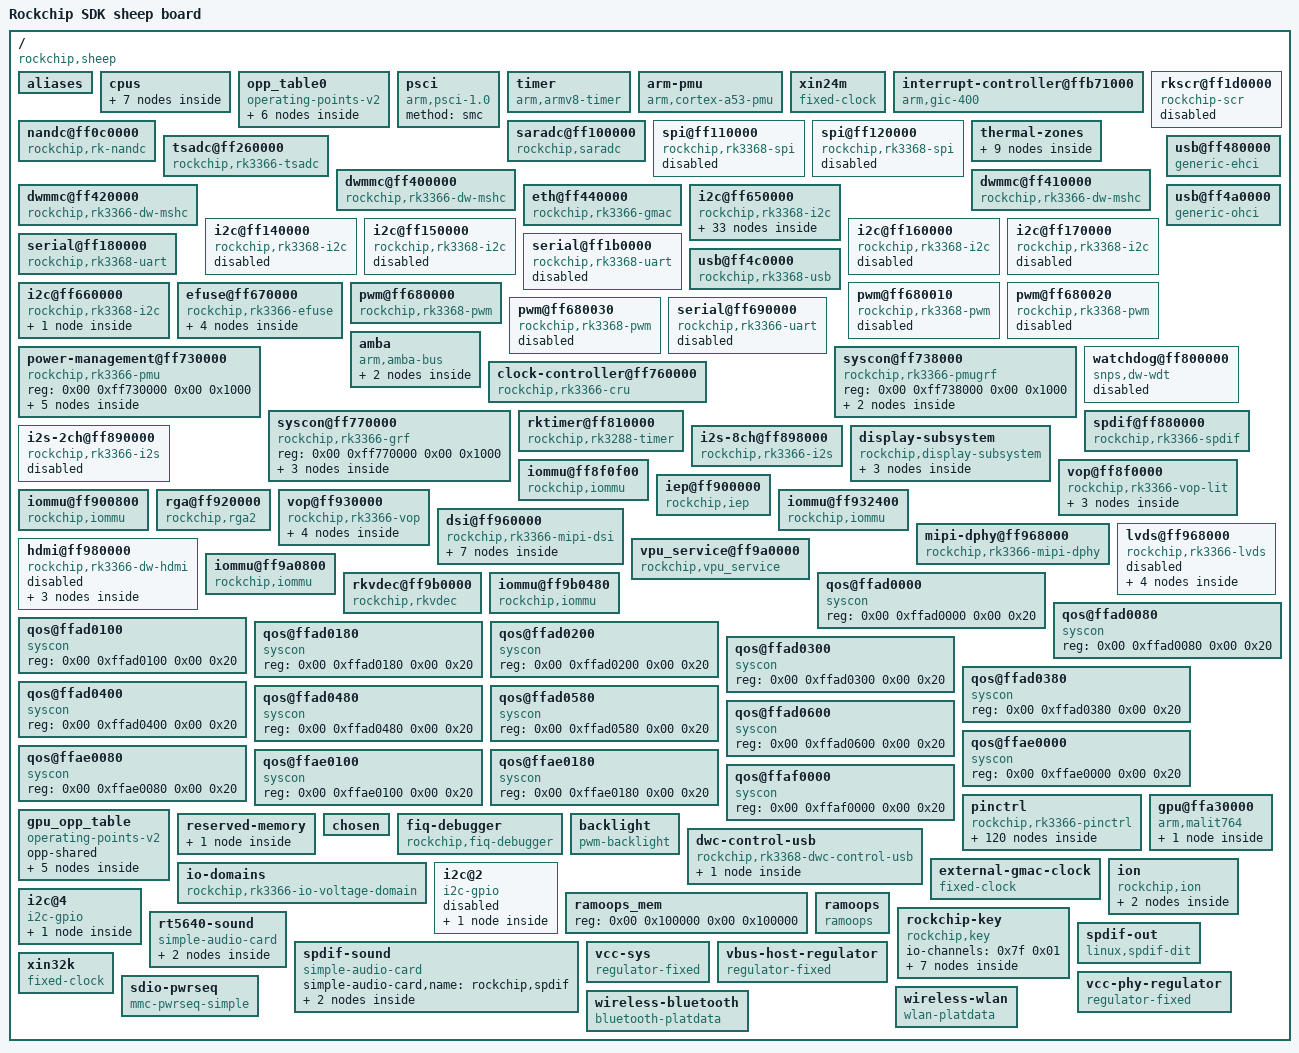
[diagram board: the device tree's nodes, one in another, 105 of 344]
/dts-v1/;

/ {
	compatible = "rockchip,sheep\0rockchip,rk3366";
	interrupt-parent = <0x01>;
	#address-cells = <0x02>;
	#size-cells = <0x02>;
	model = "Rockchip SDK sheep board";

	aliases {
		i2c0 = "/i2c@ff650000";
		i2c1 = "/i2c@ff660000";
		i2c2 = "/i2c@ff140000";
		i2c3 = "/i2c@ff150000";
		i2c4 = "/i2c@ff160000";
		i2c5 = "/i2c@ff170000";
		serial0 = "/serial@ff180000";
		serial2 = "/serial@ff690000";
		serial3 = "/serial@ff1b0000";
		spi0 = "/spi@ff110000";
		spi1 = "/spi@ff120000";
	};

	cpus {
		#address-cells = <0x02>;
		#size-cells = <0x00>;

		cpu@0 {
			device_type = "cpu";
			compatible = "arm,cortex-a53\0arm,armv8";
			reg = <0x00 0x00>;
			enable-method = "psci";
			clocks = <0x02 0x09>;
			operating-points-v2 = <0x03>;
			cpu-idle-states = <0x04 0x05>;
			#cooling-cells = <0x02>;
			dynamic-power-coefficient = <0xa6>;
			cpu-supply = <0x06>;
			phandle = <0x08>;
		};

		cpu@1 {
			device_type = "cpu";
			compatible = "arm,cortex-a53\0arm,armv8";
			reg = <0x00 0x01>;
			enable-method = "psci";
			operating-points-v2 = <0x03>;
			cpu-idle-states = <0x04 0x05>;
			cpu-supply = <0x06>;
			phandle = <0x09>;
		};

		cpu@2 {
			device_type = "cpu";
			compatible = "arm,cortex-a53\0arm,armv8";
			reg = <0x00 0x02>;
			enable-method = "psci";
			operating-points-v2 = <0x03>;
			cpu-idle-states = <0x04 0x05>;
			cpu-supply = <0x06>;
			phandle = <0x0a>;
		};

		cpu@3 {
			device_type = "cpu";
			compatible = "arm,cortex-a53\0arm,armv8";
			reg = <0x00 0x03>;
			enable-method = "psci";
			operating-points-v2 = <0x03>;
			cpu-idle-states = <0x04 0x05>;
			cpu-supply = <0x06>;
			phandle = <0x0b>;
		};

		idle-states {
			entry-method = "psci";

			cpu-sleep {
				compatible = "arm,idle-state";
				local-timer-stop;
				arm,psci-suspend-param = <0x10000>;
				entry-latency-us = <0x78>;
				exit-latency-us = <0xfa>;
				min-residency-us = <0x384>;
				phandle = <0x04>;
			};

			cluster-sleep {
				compatible = "arm,idle-state";
				local-timer-stop;
				arm,psci-suspend-param = <0x1010000>;
				entry-latency-us = <0x190>;
				exit-latency-us = <0x1f4>;
				min-residency-us = <0x7d0>;
				phandle = <0x05>;
			};
		};
	};

	opp_table0 {
		compatible = "operating-points-v2";
		opp-shared;
		nvmem-cells = <0x07>;
		nvmem-cell-names = "cpu_leakage";
		phandle = <0x03>;

		opp-408000000 {
			opp-hz = <0x00 0x18519600>;
			opp-microvolt = <0xe7ef0 0xe7ef0 0x1312d0>;
			clock-latency-ns = <0x9c40>;
			opp-suspend;
		};

		opp-600000000 {
			opp-hz = <0x00 0x23c34600>;
			opp-microvolt = <0xe7ef0 0xe7ef0 0x1312d0>;
		};

		opp-816000000 {
			opp-hz = <0x00 0x30a32c00>;
			opp-microvolt = <0xf4240 0xf4240 0x1312d0>;
		};

		opp-1008000000 {
			opp-hz = <0x00 0x3c14dc00>;
			opp-microvolt = <0x106738 0x106738 0x1312d0>;
		};

		opp-1200000000 {
			opp-hz = <0x00 0x47868c00>;
			opp-microvolt = <0x11edd8 0x11edd8 0x1312d0>;
		};

		opp-1296000000 {
			opp-hz = <0x00 0x4d3f6400>;
			opp-microvolt = <0x1312d0 0x1312d0 0x1312d0>;
		};
	};

	psci {
		compatible = "arm,psci-1.0";
		method = "smc";
	};

	timer {
		compatible = "arm,armv8-timer";
		interrupts = <0x01 0x0d 0xf04 0x01 0x0e 0xf04 0x01 0x0b 0xf04 0x01 0x0a 0xf04>;
	};

	arm-pmu {
		compatible = "arm,cortex-a53-pmu";
		interrupts = <0x00 0x70 0x04 0x00 0x71 0x04 0x00 0x72 0x04 0x00 0x73 0x04>;
		interrupt-affinity = <0x08 0x09 0x0a 0x0b>;
	};

	xin24m {
		compatible = "fixed-clock";
		#clock-cells = <0x00>;
		clock-frequency = <0x16e3600>;
		clock-output-names = "xin24m";
		phandle = <0x8b>;
	};

	interrupt-controller@ffb71000 {
		compatible = "arm,gic-400";
		interrupt-controller;
		#interrupt-cells = <0x03>;
		#address-cells = <0x00>;
		reg = <0x00 0xffb71000 0x00 0x1000 0x00 0xffb72000 0x00 0x1000 0x00 0xffb74000 0x00 0x2000 0x00 0xffb76000 0x00 0x2000>;
		interrupts = <0x01 0x09 0xf04>;
		phandle = <0x01>;
	};

	nandc@ff0c0000 {
		compatible = "rockchip,rk-nandc";
		reg = <0x00 0xff0c0000 0x00 0x4000>;
		interrupts = <0x00 0x26 0x04>;
		nandc_id = <0x00>;
		clocks = <0x02 0x64 0x02 0x1ca>;
		clock-names = "clk_nandc\0hclk_nandc";
		status = "okay";
		phandle = <0x8c>;
	};

	saradc@ff100000 {
		compatible = "rockchip,saradc";
		reg = <0x00 0xff100000 0x00 0x100>;
		interrupts = <0x00 0x24 0x04>;
		#io-channel-cells = <0x01>;
		clocks = <0x02 0x63 0x02 0x161>;
		clock-names = "saradc\0apb_pclk";
		status = "okay";
		phandle = <0x7f>;
	};

	spi@ff110000 {
		compatible = "rockchip,rk3368-spi\0rockchip,rk3066-spi";
		reg = <0x00 0xff110000 0x00 0x1000>;
		clocks = <0x02 0x4e 0x02 0x156>;
		clock-names = "spiclk\0apb_pclk";
		interrupts = <0x00 0x2c 0x04>;
		pinctrl-names = "default";
		pinctrl-0 = <0x0c 0x0d 0x0e 0x0f>;
		#address-cells = <0x01>;
		#size-cells = <0x00>;
		status = "disabled";
		phandle = <0x8d>;
	};

	spi@ff120000 {
		compatible = "rockchip,rk3368-spi\0rockchip,rk3066-spi";
		reg = <0x00 0xff120000 0x00 0x1000>;
		clocks = <0x02 0x4f 0x02 0x157>;
		clock-names = "spiclk\0apb_pclk";
		interrupts = <0x00 0x2d 0x04>;
		pinctrl-names = "default";
		pinctrl-0 = <0x10 0x11 0x12 0x13>;
		#address-cells = <0x01>;
		#size-cells = <0x00>;
		status = "disabled";
		phandle = <0x8e>;
	};

	rkscr@ff1d0000 {
		compatible = "rockchip-scr";
		reg = <0x00 0xff1d0000 0x00 0x10000>;
		interrupts = <0x00 0x2b 0x04>;
		#address-cells = <0x01>;
		#size-cells = <0x00>;
		pinctrl-names = "default";
		pinctrl-0 = <0x14 0x15 0x16 0x17>;
		clocks = <0x02 0x163>;
		clock-names = "g_pclk_sim_card";
		status = "disabled";
		phandle = <0x8f>;
	};

	thermal-zones {

		soc-thermal {
			polling-delay-passive = <0x64>;
			polling-delay = <0x3e8>;
			sustainable-power = <0x640>;
			thermal-sensors = <0x18 0x00>;
			phandle = <0x90>;

			trips {

				trip-point-0 {
					temperature = <0x11170>;
					hysteresis = <0x7d0>;
					type = "passive";
					phandle = <0x91>;
				};

				trip-point-1 {
					temperature = <0x14c08>;
					hysteresis = <0x7d0>;
					type = "passive";
					phandle = <0x19>;
				};

				soc-crit {
					temperature = <0x1c138>;
					hysteresis = <0x7d0>;
					type = "critical";
					phandle = <0x92>;
				};
			};

			cooling-maps {

				map0 {
					trip = <0x19>;
					cooling-device = <0x08 0xffffffff 0xffffffff>;
				};

				map1 {
					trip = <0x19>;
					cooling-device = <0x1a 0xffffffff 0xffffffff>;
				};
			};
		};

		gpu-thermal {
			polling-delay-passive = <0x64>;
			polling-delay = <0x3e8>;
			thermal-sensors = <0x18 0x01>;
			phandle = <0x93>;
		};
	};

	tsadc@ff260000 {
		compatible = "rockchip,rk3366-tsadc";
		reg = <0x00 0xff260000 0x00 0x100>;
		interrupts = <0x00 0x25 0x04>;
		clocks = <0x02 0x62 0x02 0x162>;
		clock-names = "tsadc\0apb_pclk";
		resets = <0x02 0x8e>;
		reset-names = "tsadc-apb";
		pinctrl-names = "gpio\0otpout";
		pinctrl-0 = <0x1b>;
		pinctrl-1 = <0x1c>;
		#thermal-sensor-cells = <0x01>;
		rockchip,hw-tshut-temp = <0x1d4c0>;
		status = "okay";
		phandle = <0x18>;
	};

	dwmmc@ff400000 {
		compatible = "rockchip,rk3366-dw-mshc\0rockchip,rk3288-dw-mshc";
		clock-freq-min-max = <0x61a80 0x23c3460>;
		clocks = <0x02 0x1c7 0x02 0x51 0x02 0x55 0x02 0x56>;
		clock-names = "biu\0ciu\0ciu-drive\0ciu-sample";
		fifo-depth = <0x100>;
		interrupts = <0x00 0x20 0x04>;
		reg = <0x00 0xff400000 0x00 0x4000>;
		status = "okay";
		clock-frequency = <0x23c3460>;
		supports-sd;
		bus-width = <0x04>;
		cap-mmc-highspeed;
		cap-sd-highspeed;
		card-detect-delay = <0xc8>;
		disable-wp;
		num-slots = <0x01>;
		pinctrl-names = "default";
		pinctrl-0 = <0x1d 0x1e 0x1f 0x20>;
		phandle = <0x94>;
	};

	dwmmc@ff410000 {
		compatible = "rockchip,rk3366-dw-mshc\0rockchip,rk3288-dw-mshc";
		clock-freq-min-max = <0x30d40 0x23c3460>;
		clocks = <0x02 0x1c8 0x02 0x52 0x02 0x57 0x02 0x58>;
		clock-names = "biu\0ciu\0ciu-drive\0ciu-sample";
		fifo-depth = <0x100>;
		interrupts = <0x00 0x21 0x04>;
		reg = <0x00 0xff410000 0x00 0x4000>;
		status = "okay";
		clock-frequency = <0x23c3460>;
		supports-sdio;
		bus-width = <0x04>;
		disable-wp;
		cap-sd-highspeed;
		cap-sdio-irq;
		keep-power-in-suspend;
		mmc-pwrseq = <0x21>;
		non-removable;
		num-slots = <0x01>;
		pinctrl-names = "default";
		pinctrl-0 = <0x22 0x23 0x24>;
		sd-uhs-sdr104;
		phandle = <0x95>;
	};

	dwmmc@ff420000 {
		compatible = "rockchip,rk3366-dw-mshc\0rockchip,rk3288-dw-mshc";
		clock-freq-min-max = <0x61a80 0x5f5e100>;
		clocks = <0x02 0x1c9 0x02 0x54 0x02 0x5b 0x02 0x5c>;
		clock-names = "biu\0ciu\0ciu-drive\0ciu-sample";
		fifo-depth = <0x100>;
		interrupts = <0x00 0x23 0x04>;
		reg = <0x00 0xff420000 0x00 0x4000>;
		status = "okay";
		clock-frequency = <0x5f5e100>;
		supports-emmc;
		bus-width = <0x08>;
		cap-mmc-highspeed;
		disable-wp;
		non-removable;
		num-slots = <0x01>;
		pinctrl-names = "default";
		pinctrl-0 = <0x25 0x26 0x27 0x28>;
		phandle = <0x96>;
	};

	eth@ff440000 {
		compatible = "rockchip,rk3366-gmac";
		reg = <0x00 0xff440000 0x00 0x10000>;
		rockchip,grf = <0x29>;
		interrupts = <0x00 0x1b 0x04>;
		interrupt-names = "macirq";
		clocks = <0x02 0x6b 0x02 0x6e 0x02 0x6f 0x02 0x6d 0x02 0x6c 0x02 0xc7 0x02 0x155>;
		clock-names = "stmmaceth\0mac_clk_rx\0mac_clk_tx\0clk_mac_ref\0clk_mac_refout\0aclk_mac\0pclk_mac";
		resets = <0x02 0x42>;
		reset-names = "stmmaceth";
		status = "okay";
		phy-supply = <0x2a>;
		phy-mode = "rgmii";
		clock_in_out = "input";
		snps,reset-gpio = <0x2b 0x0f 0x01>;
		snps,reset-active-low;
		snps,reset-delays-us = <0x00 0x2710 0xc350>;
		assigned-clocks = <0x02 0x6b>;
		assigned-clock-parents = <0x2c>;
		pinctrl-names = "default";
		pinctrl-0 = <0x2d>;
		tx_delay = <0x25>;
		rx_delay = <0x1d>;
		phandle = <0x97>;
	};

	i2c@ff650000 {
		compatible = "rockchip,rk3368-i2c\0rockchip,rk3288-i2c";
		reg = <0x00 0xff728000 0x00 0x1000>;
		clocks = <0x02 0x158>;
		clock-names = "i2c";
		interrupts = <0x00 0x3c 0x04>;
		pinctrl-names = "default";
		pinctrl-0 = <0x2e>;
		#address-cells = <0x01>;
		#size-cells = <0x00>;
		status = "okay";
		i2c-scl-rising-time-ns = <0xfa>;
		i2c-scl-falling-time-ns = <0x14>;
		phandle = <0x98>;

		syr827@40 {
			regulator-name = "vdd_arm";
			compatible = "silergy,syr827";
			status = "okay";
			reg = <0x40>;
			regulator-compatible = "fan53555-reg";
			regulator-min-microvolt = <0xadf34>;
			regulator-max-microvolt = <0x16e360>;
			fcs,suspend-voltage-selector = <0x01>;
			regulator-always-on;
			regulator-boot-on;
			regulator-initial-state = <0x03>;
			regulator-ramp-delay = <0x7d0>;
			phandle = <0x06>;

			regulator-state-mem {
				regulator-off-in-suspend;
				regulator-suspend-microvolt = <0xdbba0>;
			};
		};

		pmic@1c {
			compatible = "rockchip,rk818";
			status = "okay";
			reg = <0x1c>;
			clock-output-names = "rk818-clkout1\0wifibt_32kin";
			interrupt-parent = <0x2f>;
			interrupts = <0x02 0x08>;
			pinctrl-names = "default";
			pinctrl-0 = <0x30>;
			rockchip,system-power-controller;
			wakeup-source;
			#clock-cells = <0x01>;
			vcc1-supply = <0x31>;
			vcc2-supply = <0x31>;
			vcc3-supply = <0x31>;
			vcc4-supply = <0x31>;
			vcc6-supply = <0x31>;
			vcc7-supply = <0x31>;
			vcc8-supply = <0x31>;
			vcc9-supply = <0x32>;
			phandle = <0x86>;

			regulators {

				DCDC_REG1 {
					regulator-name = "vdd_logic";
					regulator-always-on;
					regulator-boot-on;
					regulator-min-microvolt = <0xb71b0>;
					regulator-max-microvolt = <0x162010>;
					regulator-ramp-delay = <0x1771>;
					phandle = <0x74>;

					regulator-state-mem {
						regulator-on-in-suspend;
						regulator-suspend-microvolt = <0xf4240>;
					};
				};

				DCDC_REG2 {
					regulator-name = "vdd_gpu";
					regulator-always-on;
					regulator-boot-on;
					regulator-min-microvolt = "\0\f5";
					regulator-max-microvolt = <0x1312d0>;
					regulator-ramp-delay = <0x1771>;
					phandle = <0x99>;

					regulator-state-mem {
						regulator-on-in-suspend;
						regulator-suspend-microvolt = <0xf4240>;
					};
				};

				DCDC_REG3 {
					regulator-name = "vcc_ddr";
					regulator-always-on;
					regulator-boot-on;
					phandle = <0x9a>;

					regulator-state-mem {
						regulator-on-in-suspend;
					};
				};

				DCDC_REG4 {
					regulator-name = "vcc_io";
					regulator-always-on;
					regulator-boot-on;
					regulator-min-microvolt = <0x325aa0>;
					regulator-max-microvolt = <0x325aa0>;
					phandle = <0x32>;

					regulator-state-mem {
						regulator-on-in-suspend;
						regulator-suspend-microvolt = <0x325aa0>;
					};
				};

				LDO_REG1 {
					regulator-name = "vcca_codec";
					regulator-always-on;
					regulator-boot-on;
					regulator-min-microvolt = <0x325aa0>;
					regulator-max-microvolt = <0x325aa0>;
					phandle = <0x9b>;

					regulator-state-mem {
						regulator-on-in-suspend;
						regulator-suspend-microvolt = <0x325aa0>;
					};
				};

				LDO_REG2 {
					regulator-name = "vcc_tp";
					regulator-always-on;
					regulator-boot-on;
					regulator-min-microvolt = <0x2dc6c0>;
					regulator-max-microvolt = <0x2dc6c0>;
					phandle = <0x7d>;

					regulator-state-mem {
						regulator-on-in-suspend;
						regulator-suspend-microvolt = <0x2dc6c0>;
					};
				};

				LDO_REG3 {
					regulator-name = "vdd_10";
					regulator-always-on;
					regulator-boot-on;
					regulator-min-microvolt = <0xf4240>;
					regulator-max-microvolt = <0xf4240>;
					phandle = <0x9c>;

					regulator-state-mem {
						regulator-on-in-suspend;
						regulator-suspend-microvolt = <0xf4240>;
					};
				};

				LDO_REG4 {
					regulator-name = "vcc18_lcd";
					regulator-always-on;
					regulator-boot-on;
					regulator-min-microvolt = <0x1b7740>;
					regulator-max-microvolt = <0x1b7740>;
					phandle = <0x9d>;

					regulator-state-mem {
						regulator-on-in-suspend;
						regulator-suspend-microvolt = <0x1b7740>;
					};
				};

				LDO_REG5 {
					regulator-name = "vccio_pmu";
					regulator-always-on;
					regulator-boot-on;
					regulator-min-microvolt = <0x1b7740>;
					regulator-max-microvolt = <0x1b7740>;
					phandle = <0x9e>;

					regulator-state-mem {
						regulator-on-in-suspend;
						regulator-suspend-microvolt = <0x1b7740>;
					};
				};

				LDO_REG6 {
					regulator-name = "vdd10_lcd";
					regulator-always-on;
					regulator-boot-on;
					regulator-min-microvolt = <0xf4240>;
					regulator-max-microvolt = <0xf4240>;
					phandle = <0x9f>;

					regulator-state-mem {
						regulator-on-in-suspend;
						regulator-suspend-microvolt = <0xf4240>;
					};
				};

				LDO_REG7 {
					regulator-name = "vcc_18";
					regulator-always-on;
					regulator-boot-on;
					regulator-min-microvolt = <0x1b7740>;
					regulator-max-microvolt = <0x1b7740>;
					phandle = <0x76>;

					regulator-state-mem {
						regulator-on-in-suspend;
						regulator-suspend-microvolt = <0x1b7740>;
					};
				};

				LDO_REG8 {
					regulator-name = "vccio_wl";
					regulator-always-on;
					regulator-boot-on;
					regulator-min-microvolt = <0x1b7740>;
					regulator-max-microvolt = <0x325aa0>;
					phandle = <0x77>;

					regulator-state-mem {
						regulator-on-in-suspend;
						regulator-suspend-microvolt = <0x325aa0>;
					};
				};

				LDO_REG9 {
					regulator-name = "vccio_sd";
					regulator-always-on;
					regulator-boot-on;
					regulator-min-microvolt = <0x1b7740>;
					regulator-max-microvolt = <0x325aa0>;
					phandle = <0x78>;

					regulator-state-mem {
						regulator-on-in-suspend;
						regulator-suspend-microvolt = <0x325aa0>;
					};
				};

				SWITCH_REG {
					regulator-name = "vcc_sd";
					regulator-always-on;
					regulator-boot-on;
					phandle = <0xa0>;

					regulator-state-mem {
						regulator-on-in-suspend;
					};
				};
			};

			battery {
				compatible = "rk818-battery";
				ocv_table = <0xd48 0xe42 0xe6d 0xe7b 0xe93 0xea5 0xeb0 0xeba 0xec6 0xed4 0xee4 0xef5 0xf0c 0xf2a 0xf4b 0xf6f 0xf8d 0xfcf 0xff6 0x1024 0x1056>;
				design_capacity = <0x1eec>;
				design_qmax = <0x2204>;
				bat_res = <0x41>;
				max_input_current = <0x7d0>;
				max_chrg_current = <0x640>;
				max_chrg_voltage = <0x1068>;
				sleep_enter_current = <0x12c>;
				sleep_exit_current = <0x12c>;
				power_off_thresd = <0xd48>;
				zero_algorithm_vol = <0xf0a>;
				fb_temperature = <0x69>;
				sample_res = <0x14>;
				max_soc_offset = <0x3c>;
				energy_mode = <0x00>;
				monitor_sec = <0x05>;
				virtual_power = <0x00>;
				power_dc2otg = <0x00>;
			};
		};
	};

	i2c@ff140000 {
		compatible = "rockchip,rk3368-i2c\0rockchip,rk3288-i2c";
		reg = <0x00 0xff140000 0x00 0x1000>;
		interrupts = <0x00 0x3e 0x04>;
		#address-cells = <0x01>;
		#size-cells = <0x00>;
		clock-names = "i2c";
		clocks = <0x02 0x15a>;
		pinctrl-names = "default";
		pinctrl-0 = <0x33>;
		status = "disabled";
		phandle = <0xa1>;
	};

	i2c@ff150000 {
		compatible = "rockchip,rk3368-i2c\0rockchip,rk3288-i2c";
		reg = <0x00 0xff150000 0x00 0x1000>;
		interrupts = <0x00 0x3f 0x04>;
		#address-cells = <0x01>;
		#size-cells = <0x00>;
		clock-names = "i2c";
		clocks = <0x02 0x15b>;
		pinctrl-names = "default";
		pinctrl-0 = <0x34>;
		status = "disabled";
		phandle = <0xa2>;
	};

	i2c@ff160000 {
		compatible = "rockchip,rk3368-i2c\0rockchip,rk3288-i2c";
		reg = <0x00 0xff160000 0x00 0x1000>;
		interrupts = <0x00 0x40 0x04>;
		#address-cells = <0x01>;
		#size-cells = <0x00>;
		clock-names = "i2c";
		clocks = <0x02 0x15c>;
		pinctrl-names = "default";
		pinctrl-0 = <0x35>;
		status = "disabled";
		phandle = <0xa3>;
	};

	i2c@ff170000 {
		compatible = "rockchip,rk3368-i2c\0rockchip,rk3288-i2c";
		reg = <0x00 0xff170000 0x00 0x1000>;
		interrupts = <0x00 0x41 0x04>;
		#address-cells = <0x01>;
		#size-cells = <0x00>;
		clock-names = "i2c";
		clocks = <0x02 0x15d>;
		pinctrl-names = "default";
		pinctrl-0 = <0x36>;
		status = "disabled";
		phandle = <0xa4>;
	};

	serial@ff180000 {
		compatible = "rockchip,rk3368-uart\0snps,dw-apb-uart";
		reg = <0x00 0xff180000 0x00 0x100>;
		clock-frequency = <0x16e3600>;
		clocks = <0x02 0x66 0x02 0x15e>;
		clock-names = "baudclk\0apb_pclk";
		interrupts = <0x00 0x37 0x04>;
		reg-shift = <0x02>;
		reg-io-width = <0x04>;
		pinctrl-names = "default";
		pinctrl-0 = <0x37 0x38>;
		status = "okay";
		phandle = <0xa5>;
	};

	serial@ff1b0000 {
		compatible = "rockchip,rk3368-uart\0snps,dw-apb-uart";
		reg = <0x00 0xff1b0000 0x00 0x100>;
		clock-frequency = <0x16e3600>;
		clocks = <0x02 0x69 0x02 0x160>;
		clock-names = "baudclk\0apb_pclk";
		interrupts = <0x00 0x3a 0x04>;
		reg-shift = <0x02>;
		reg-io-width = <0x04>;
		pinctrl-names = "default";
		pinctrl-0 = <0x39 0x3a 0x3b>;
		status = "disabled";
		phandle = <0xa6>;
	};

	usb@ff480000 {
		compatible = "generic-ehci";
		reg = <0x00 0xff480000 0x00 0x20000>;
		interrupts = <0x00 0x18 0x04>;
		clocks = <0x02 0x79 0x02 0x1c6>;
		clock-names = "usbphy_480m\0hclk_host0";
		phys = <0x3c>;
		phy-names = "usb";
		status = "okay";
		assigned-clocks = <0x02 0x79>;
		assigned-clock-parents = <0x3d>;
		phandle = <0xa7>;
	};

	usb@ff4a0000 {
		compatible = "generic-ohci";
		reg = <0x00 0xff4a0000 0x00 0x20000>;
		interrupts = <0x00 0x19 0x04>;
		clocks = <0x02 0x79 0x02 0x1c6>;
		clock-names = "usbphy_480m\0hclk_host0";
		phys = <0x3c>;
		phy-names = "usb";
		status = "okay";
		phandle = <0xa8>;
	};

	usb@ff4c0000 {
		compatible = "rockchip,rk3368-usb\0rockchip,rk3066-usb\0snps,dwc2";
		reg = <0x00 0xff4c0000 0x00 0x40000>;
		interrupts = <0x00 0x17 0x04>;
		clocks = <0x02 0x79 0x02 0x1c5>;
		clock-names = "usbphy_480m\0otg";
		dr_mode = "otg";
		g-np-tx-fifo-size = <0x10>;
		g-rx-fifo-size = <0x118>;
		g-tx-fifo-size = <0x100 0x80 0x80 0x40 0x20 0x10>;
		g-use-dma;
		status = "okay";
		resets = <0x02 0x84 0x02 0x85 0x02 0x86>;
		reset-names = "otg_ahb\0otg_phy\0otg_controller";
		rockchip,usb-mode = <0x00>;
		phandle = <0xa9>;
	};

	i2c@ff660000 {
		compatible = "rockchip,rk3368-i2c\0rockchip,rk3288-i2c";
		reg = <0x00 0xff660000 0x00 0x1000>;
		interrupts = <0x00 0x3d 0x04>;
		#address-cells = <0x01>;
		#size-cells = <0x00>;
		clock-names = "i2c";
		clocks = <0x02 0x159>;
		pinctrl-names = "default";
		pinctrl-0 = <0x3e>;
		status = "okay";
		i2c-scl-rising-time-ns = <0x1cc>;
		i2c-scl-falling-time-ns = <0x0f>;
		phandle = <0xaa>;

		rt5640@1c {
			#sound-dai-cells = <0x00>;
			compatible = "realtek,rt5640";
			reg = <0x1c>;
			clocks = <0x02 0x41>;
			clock-names = "mclk";
			realtek,in1-differential;
			phandle = <0x81>;
		};
	};

	efuse@ff670000 {
		compatible = "rockchip,rk3366-efuse";
		reg = <0x00 0xff670000 0x00 0x20>;
		#address-cells = <0x01>;
		#size-cells = <0x01>;
		clocks = <0x02 0x16f>;
		clock-names = "pclk_efuse";
		phandle = <0xab>;

		cpu-leakage {
			reg = <0x17 0x01>;
			phandle = <0x07>;
		};

		gpu-leakage {
			reg = <0x18 0x01>;
			phandle = <0xac>;
		};

		logic-leakage {
			reg = <0x19 0x01>;
			phandle = <0xad>;
		};

		wafer-info {
			reg = <0x1c 0x01>;
			phandle = <0xae>;
		};
	};

	pwm@ff680000 {
		compatible = "rockchip,rk3368-pwm\0rockchip,rk3288-pwm";
		reg = <0x00 0xff680000 0x00 0x10>;
		#pwm-cells = <0x03>;
		pinctrl-names = "active";
		pinctrl-0 = <0x3f>;
		clocks = <0x02 0x154>;
		clock-names = "pwm";
		status = "okay";
		phandle = <0x75>;
	};

	pwm@ff680010 {
		compatible = "rockchip,rk3368-pwm\0rockchip,rk3288-pwm";
		reg = <0x00 0xff680010 0x00 0x10>;
		#pwm-cells = <0x03>;
		pinctrl-names = "active";
		pinctrl-0 = <0x40>;
		clocks = <0x02 0x154>;
		clock-names = "pwm";
		status = "disabled";
		phandle = <0xaf>;
	};

	pwm@ff680020 {
		compatible = "rockchip,rk3368-pwm\0rockchip,rk3288-pwm";
		reg = <0x00 0xff680020 0x00 0x10>;
		#pwm-cells = <0x03>;
		clocks = <0x02 0x154>;
		clock-names = "pwm";
		status = "disabled";
		phandle = <0xb0>;
	};

	pwm@ff680030 {
		compatible = "rockchip,rk3368-pwm\0rockchip,rk3288-pwm";
		reg = <0x00 0xff680030 0x00 0x10>;
		#pwm-cells = <0x03>;
		pinctrl-names = "active";
		pinctrl-0 = <0x41>;
		clocks = <0x02 0x154>;
		clock-names = "pwm";
		status = "disabled";
		phandle = <0xb1>;
	};

	serial@ff690000 {
		compatible = "rockchip,rk3366-uart\0snps,dw-apb-uart";
		reg = <0x00 0xff690000 0x00 0x100>;
		interrupts = <0x00 0x39 0x04>;
		clocks = <0x02 0x68 0x02 0x15f>;
		clock-names = "baudclk\0apb_pclk";
		reg-shift = <0x02>;
		reg-io-width = <0x04>;
		pinctrl-names = "default";
		pinctrl-0 = <0x42>;
		status = "disabled";
		phandle = <0xb2>;
	};

	power-management@ff730000 {
		compatible = "rockchip,rk3366-pmu\0syscon\0simple-mfd";
		reg = <0x00 0xff730000 0x00 0x1000>;
		phandle = <0xb3>;

		power-controller {
			compatible = "rockchip,rk3366-power-controller";
			#power-domain-cells = <0x01>;
			#address-cells = <0x01>;
			#size-cells = <0x00>;
			phandle = <0x5c>;

			pd_vio@6 {
				reg = <0x06>;
				clocks = <0x02 0xcc 0x02 0xd0 0x02 0xcb 0x02 0xd1 0x02 0xce 0x02 0xcd 0x02 0xcf 0x02 0xaa 0x02 0xab 0x02 0x1d0 0x02 0x1ce 0x02 0x1cf 0x02 0x1d1 0x02 0x1d2 0x02 0x1d6 0x02 0x14d 0x02 0x165 0x02 0x164 0x02 0x16c 0x02 0x46 0x02 0x4b 0x02 0x47 0x02 0x45 0x02 0x49 0x02 0x48>;
				pm_qos = <0x43 0x44 0x45 0x46 0x47 0x48 0x49 0x4a 0x4b 0x4c 0x4d>;
			};

			pd_vpu@10 {
				reg = <0x0a>;
				clocks = <0x02 0xc9 0x02 0x1cc>;
				pm_qos = <0x4e 0x4f>;
			};

			pd_rkvdec@8 {
				reg = <0x08>;
				clocks = <0x02 0xca 0x02 0x1cd 0x02 0x7d 0x02 0x7e>;
				pm_qos = <0x50 0x51>;
			};

			pd_gpu@11 {
				reg = <0x0b>;
				clocks = <0x02 0xc4>;
				pm_qos = <0x52>;
			};
		};
	};

	syscon@ff738000 {
		compatible = "rockchip,rk3366-pmugrf\0syscon\0simple-mfd";
		reg = <0x00 0xff738000 0x00 0x1000>;
		phandle = <0x6f>;

		reboot-mode {
			compatible = "syscon-reboot-mode";
			offset = <0x200>;
			mode-normal = <0x5242c300>;
			mode-recovery = <0x5242c303>;
			mode-fastboot = <0x5242c309>;
			mode-loader = <0x5242c301>;
		};

		pmu-pvtm {
			compatible = "rockchip,rk3366-pmu-pvtm";
			clocks = <0x02 0x81>;
			clock-names = "pmu";
			status = "okay";
			phandle = <0xb4>;
		};
	};

	amba {
		compatible = "arm,amba-bus";
		#address-cells = <0x02>;
		#size-cells = <0x02>;
		ranges;

		dma-controller@ff250000 {
			compatible = "arm,pl330\0arm,primecell";
			reg = <0x00 0xff250000 0x00 0x4000>;
			interrupts = <0x00 0x02 0x04 0x00 0x03 0x04>;
			#dma-cells = <0x01>;
			clocks = <0x02 0xc8>;
			clock-names = "apb_pclk";
			peripherals-req-type-burst;
			phandle = <0xb5>;
		};

		dma-controller@ff600000 {
			compatible = "arm,pl330\0arm,primecell";
			reg = <0x00 0xff600000 0x00 0x4000>;
			interrupts = <0x00 0x00 0x04 0x00 0x01 0x04>;
			#dma-cells = <0x01>;
			clocks = <0x02 0xc2>;
			clock-names = "apb_pclk";
			peripherals-req-type-burst;
			phandle = <0x54>;
		};
	};

	clock-controller@ff760000 {
		compatible = "rockchip,rk3366-cru";
		reg = <0x00 0xff760000 0x00 0x1000>;
		rockchip,grf = <0x29>;
		#clock-cells = <0x01>;
		#reset-cells = <0x01>;
		assigned-clocks = <0x02 0x72 0x02 0x84 0x02 0xaa 0x02 0xab 0x02 0x85 0x02 0x86 0x02 0x87 0x02 0x03 0x02 0x04 0x02 0x05 0x02 0x06 0x02 0x07 0x02 0x08 0x02 0xce 0x02 0xcd 0x02 0x1d2 0x02 0x1d2 0x02 0xd2 0x02 0xd3 0x02 0xd4>;
		assigned-clock-rates = <0x00 0x00 0x00 0x00 0x00 0x00 0x00 0x2cb41780 0x22551000 0x2367b880 0x2367b880 0x39387000 0x1efe9200 0x165a0bc0 0x112a8800 0x5f5e100 0x5f5e100 0x112a8800 0x112a8800 0x8954400>;
		assigned-clock-parents = <0x02 0x7a 0x02 0x83 0x02 0x82 0x02 0x05 0x02 0x04 0x02 0x04 0x02 0x04>;
		phandle = <0x02>;
	};

	syscon@ff770000 {
		compatible = "rockchip,rk3366-grf\0syscon\0simple-mfd";
		reg = <0x00 0xff770000 0x00 0x1000>;
		#address-cells = <0x01>;
		#size-cells = <0x01>;
		phandle = <0x29>;

		usb2-phy@700 {
			compatible = "rockchip,rk3366-usb2phy";
			reg = <0x700 0x2c>;
			clocks = <0x02 0x5d>;
			clock-names = "phyclk";
			#clock-cells = <0x00>;
			clock-output-names = "sclk_otgphy0_480m";
			phandle = <0x3d>;

			host-port {
				#phy-cells = <0x00>;
				interrupts = <0x00 0x60 0x04>;
				interrupt-names = "linestate";
				status = "okay";
				phy-supply = <0x53>;
				phandle = <0x3c>;
			};
		};

		pvtm {
			compatible = "rockchip,rk3366-pvtm";
			clocks = <0x02 0x4c 0x02 0x4d>;
			clock-names = "core\0gpu";
			status = "okay";
			phandle = <0xb6>;
		};
	};

	watchdog@ff800000 {
		compatible = "snps,dw-wdt";
		reg = <0x00 0xff800000 0x00 0x100>;
		clocks = <0x02 0x167>;
		interrupts = <0x00 0x4f 0x04>;
		status = "disabled";
		phandle = <0xb7>;
	};

	rktimer@ff810000 {
		compatible = "rockchip,rk3288-timer";
		reg = <0x00 0xff810000 0x00 0x1000>;
		interrupts = <0x00 0x42 0x04>;
		clocks = <0x02 0x14e 0x02 0x73>;
		clock-names = "pclk\0timer";
		phandle = <0xb8>;
	};

	spdif@ff880000 {
		compatible = "rockchip,rk3366-spdif";
		reg = <0x00 0xff880000 0x00 0x1000>;
		interrupts = <0x00 0x36 0x04>;
		dmas = <0x54 0x03>;
		dma-names = "tx";
		clock-names = "mclk\0hclk";
		clocks = <0x02 0x44 0x02 0x1c2>;
		pinctrl-names = "default";
		pinctrl-0 = <0x55>;
		status = "okay";
		#sound-dai-cells = <0x00>;
		phandle = <0x82>;
	};

	i2s-2ch@ff890000 {
		compatible = "rockchip,rk3366-i2s\0rockchip,rk3066-i2s";
		reg = <0x00 0xff890000 0x00 0x1000>;
		interrupts = <0x00 0x28 0x04>;
		dmas = <0x54 0x06 0x54 0x07>;
		dma-names = "tx\0rx";
		clock-names = "i2s_clk\0i2s_hclk";
		clocks = <0x02 0x43 0x02 0x1c1>;
		resets = <0x02 0x19>;
		reset-names = "reset-m";
		status = "disabled";
		phandle = <0xb9>;
	};

	i2s-8ch@ff898000 {
		compatible = "rockchip,rk3366-i2s\0rockchip,rk3066-i2s";
		reg = <0x00 0xff898000 0x00 0x1000>;
		interrupts = <0x00 0x35 0x04>;
		dmas = <0x54 0x00 0x54 0x01>;
		dma-names = "tx\0rx";
		clock-names = "i2s_clk\0i2s_hclk";
		clocks = <0x02 0x42 0x02 0x1c0>;
		resets = <0x02 0x17>;
		reset-names = "reset-m";
		pinctrl-names = "default";
		pinctrl-0 = <0x56>;
		status = "okay";
		rockchip,i2s-broken-burst-len;
		rockchip,playback-channels = <0x08>;
		rockchip,capture-channels = <0x02>;
		#sound-dai-cells = <0x00>;
		phandle = <0x80>;
	};

	display-subsystem {
		compatible = "rockchip,display-subsystem";
		ports = <0x57 0x58>;
		status = "okay";
		logo-memory-region = <0x59>;
		phandle = <0xba>;

		route {

			route-dsi {
				logo,uboot = "logo.bmp";
				logo,kernel = "logo_kernel.bmp";
				logo,mode = "center";
				charge_logo,mode = "center";
				connect = <0x5a>;
				status = "okay";
				phandle = <0xbb>;
			};

			route-lvds {
				logo,uboot = "logo.bmp";
				logo,kernel = "logo_kernel.bmp";
				logo,mode = "center";
				charge_logo,mode = "center";
				connect = <0x5b>;
				status = "disabled";
				phandle = <0xbc>;
			};
		};
	};

	vop@ff8f0000 {
		compatible = "rockchip,rk3366-vop-lit";
		reg = <0x00 0xff8f0000 0x00 0x900>;
		interrupts = <0x00 0x14 0x04>;
		clocks = <0x02 0xcd 0x02 0xab 0x02 0x1d2>;
		clock-names = "aclk_vop\0dclk_vop\0hclk_vop";
		resets = <0x02 0x5d 0x02 0x5f 0x02 0x5e>;
		reset-names = "axi\0ahb\0dclk";
		power-domains = <0x5c 0x06>;
		iommus = <0x5d>;
		status = "okay";
		phandle = <0xbd>;

		port {
			#address-cells = <0x01>;
			#size-cells = <0x00>;
			phandle = <0x58>;

			endpoint@0 {
				reg = <0x00>;
				remote-endpoint = <0x5e>;
				phandle = <0x66>;
			};

			endpoint@1 {
				reg = <0x01>;
				remote-endpoint = <0x5f>;
				phandle = <0x69>;
			};
		};
	};

	iommu@ff8f0f00 {
		compatible = "rockchip,iommu";
		reg = <0x00 0xff8f0f00 0x00 0x100>;
		interrupts = <0x00 0x14 0x04>;
		interrupt-names = "vopl_mmu";
		clocks = <0x02 0xcd 0x02 0x1d2>;
		clock-names = "aclk\0hclk";
		power-domains = <0x5c 0x06>;
		#iommu-cells = <0x00>;
		status = "okay";
		phandle = <0x5d>;
	};

	iep@ff900000 {
		compatible = "rockchip,iep";
		iommu_enabled = <0x01>;
		iommus = <0x60>;
		reg = <0x00 0xff900000 0x00 0x800>;
		interrupts = <0x00 0x11 0x04>;
		clocks = <0x02 0xcc 0x02 0x1d0>;
		clock-names = "aclk_iep\0hclk_iep";
		power-domains = <0x5c 0x06>;
		allocator = <0x01>;
		version = <0x02>;
		status = "okay";
		phandle = <0xbe>;
	};

	iommu@ff900800 {
		compatible = "rockchip,iommu";
		reg = <0x00 0xff900800 0x00 0x100>;
		interrupts = <0x00 0x11 0x04>;
		interrupt-names = "iep_mmu";
		power-domains = <0x5c 0x06>;
		#iommu-cells = <0x00>;
		status = "okay";
		phandle = <0x60>;
	};

	rga@ff920000 {
		compatible = "rockchip,rga2";
		dev_mode = <0x01>;
		reg = <0x00 0xff920000 0x00 0x1000>;
		interrupts = <0x00 0x12 0x04>;
		clocks = <0x02 0xcb 0x02 0x1cf 0x02 0x45>;
		clock-names = "aclk_rga\0hclk_rga\0clk_rga";
		power-domains = <0x5c 0x06>;
		dma-coherent;
		status = "okay";
		phandle = <0xbf>;
	};

	vop@ff930000 {
		compatible = "rockchip,rk3366-vop";
		reg = <0x00 0xff930000 0x00 0x1ffc>;
		interrupts = <0x00 0x0f 0x04>;
		clocks = <0x02 0xce 0x02 0xaa 0x02 0x1d1>;
		clock-names = "aclk_vop\0dclk_vop\0hclk_vop";
		power-domains = <0x5c 0x06>;
		resets = <0x02 0x64 0x02 0x66 0x02 0x65>;
		reset-names = "axi\0ahb\0dclk";
		iommus = <0x61>;
		status = "okay";
		phandle = <0xc0>;

		port {
			#address-cells = <0x01>;
			#size-cells = <0x00>;
			phandle = <0x57>;

			endpoint@0 {
				reg = <0x00>;
				remote-endpoint = <0x62>;
				phandle = <0x5a>;
			};

			endpoint@1 {
				reg = <0x01>;
				remote-endpoint = <0x63>;
				phandle = <0x5b>;
			};

			endpoint@2 {
				reg = <0x02>;
				remote-endpoint = <0x64>;
				phandle = <0x6c>;
			};
		};
	};

	iommu@ff932400 {
		compatible = "rockchip,iommu";
		reg = <0x00 0xff932400 0x00 0x100>;
		interrupts = <0x00 0x0f 0x04>;
		interrupt-names = "vop_mmu";
		clocks = <0x02 0xce 0x02 0x1d1>;
		clock-names = "aclk\0hclk";
		power-domains = <0x5c 0x06>;
		#iommu-cells = <0x00>;
		status = "okay";
		phandle = <0x61>;
	};

	dsi@ff960000 {
		compatible = "rockchip,rk3366-mipi-dsi";
		reg = <0x00 0xff960000 0x00 0x4000>;
		interrupts = <0x00 0x13 0x04>;
		clocks = <0x02 0x16c 0x65>;
		clock-names = "pclk\0hs_clk";
		resets = <0x02 0x73>;
		reset-names = "apb";
		phys = <0x65>;
		phy-names = "mipi_dphy";
		power-domains = <0x5c 0x06>;
		rockchip,grf = <0x29>;
		#address-cells = <0x01>;
		#size-cells = <0x00>;
		status = "okay";
		phandle = <0xc1>;

		ports {

			port {
				#address-cells = <0x01>;
				#size-cells = <0x00>;

				endpoint@0 {
					reg = <0x00>;
					remote-endpoint = <0x5a>;
					phandle = <0x62>;
				};

				endpoint@1 {
					reg = <0x01>;
					remote-endpoint = <0x66>;
					phandle = <0x5e>;
				};
			};
		};

		panel@0 {
			compatible = "simple-panel-dsi";
			reg = <0x00>;
			backlight = <0x67>;
			enable-gpios = <0x2f 0x0c 0x00>;
			prepare-delay-ms = <0x14>;
			enable-delay-ms = <0x14>;
			dsi,flags = <0x03>;
			dsi,format = <0x00>;
			dsi,lanes = <0x04>;

			display-timings {
				native-mode = <0x68>;

				timing0 {
					clock-frequency = <0x80befc0>;
					hactive = <0x4b0>;
					vactive = <0x780>;
					hfront-porch = <0x50>;
					hsync-len = <0x14>;
					hback-porch = <0x50>;
					vfront-porch = <0x15>;
					vsync-len = <0x03>;
					vback-porch = <0x15>;
					hsync-active = <0x00>;
					vsync-active = <0x00>;
					de-active = <0x00>;
					pixelclk-active = <0x00>;
					phandle = <0x68>;
				};
			};
		};
	};

	mipi-dphy@ff968000 {
		compatible = "rockchip,rk3366-mipi-dphy";
		reg = <0x00 0xff968000 0x00 0x4000>;
		clocks = <0x02 0x7c 0x02 0x14d>;
		clock-names = "ref\0pclk";
		clock-output-names = "mipi_dphy_pll";
		#clock-cells = <0x00>;
		resets = <0x02 0x72>;
		reset-names = "apb";
		power-domains = <0x5c 0x06>;
		rockchip,grf = <0x29>;
		#phy-cells = <0x00>;
		status = "okay";
		phandle = <0x65>;
	};

	lvds@ff968000 {
		compatible = "rockchip,rk3366-lvds";
		reg = <0x00 0xff968000 0x00 0x4000 0x00 0xff960000 0x00 0x100>;
		reg-names = "mipi_lvds_phy\0mipi_lvds_ctl";
		clocks = <0x02 0x14d 0x02 0x16c>;
		clock-names = "pclk_lvds\0pclk_lvds_ctl";
		power-domains = <0x5c 0x06>;
		rockchip,grf = <0x29>;
		status = "disabled";
		phandle = <0xc2>;

		ports {
			#address-cells = <0x01>;
			#size-cells = <0x00>;

			port@0 {
				reg = <0x00>;
				#address-cells = <0x01>;
				#size-cells = <0x00>;

				endpoint@0 {
					reg = <0x00>;
					remote-endpoint = <0x5b>;
					phandle = <0x63>;
				};

				endpoint@1 {
					reg = <0x01>;
					remote-endpoint = <0x69>;
					phandle = <0x5f>;
				};
			};
		};
	};

	hdmi@ff980000 {
		compatible = "rockchip,rk3366-dw-hdmi";
		reg = <0x00 0xff980000 0x00 0x20000>;
		reg-io-width = <0x04>;
		interrupts = <0x00 0x67 0x04 0x00 0x66 0x04>;
		clocks = <0x02 0x165 0x02 0x48 0x02 0x49 0x02 0xac>;
		clock-names = "iahb\0isfr\0cec\0dclk";
		pinctrl-names = "default";
		pinctrl-0 = <0x6a 0x6b>;
		resets = <0x02 0x79>;
		reset-names = "hdmi";
		rockchip,grf = <0x29>;
		status = "disabled";
		phandle = <0xc3>;

		ports {

			port {
				#address-cells = <0x01>;
				#size-cells = <0x00>;

				endpoint@0 {
					reg = <0x00>;
					remote-endpoint = <0x6c>;
					phandle = <0x64>;
				};
			};
		};
	};

	vpu_service@ff9a0000 {
		compatible = "rockchip,vpu_service";
		rockchip,grf = <0x29>;
		iommu_enabled = <0x01>;
		iommus = <0x6d>;
		reg = <0x00 0xff9a0000 0x00 0x800>;
		interrupts = <0x00 0x0b 0x04 0x00 0x09 0x04>;
		interrupt-names = "irq_dec\0irq_enc";
		clocks = <0x02 0xc9 0x02 0x1cc>;
		clock-names = "aclk_vcodec\0hclk_vcodec";
		power-domains = <0x5c 0x0a>;
		resets = <0x02 0x71 0x02 0x70>;
		reset-names = "video_h\0video_a";
		dev_mode = <0x00>;
		allocator = <0x01>;
		status = "okay";
		phandle = <0xc4>;
	};

	iommu@ff9a0800 {
		compatible = "rockchip,iommu";
		reg = <0x00 0xff9a0800 0x00 0x100>;
		interrupts = <0x00 0x0a 0x04>;
		interrupt-names = "vpu_mmu";
		clocks = <0x02 0xc9 0x02 0x1cc>;
		clock-names = "aclk\0hclk";
		power-domains = <0x5c 0x0a>;
		#iommu-cells = <0x00>;
		status = "okay";
		phandle = <0x6d>;
	};

	rkvdec@ff9b0000 {
		compatible = "rockchip,rkvdec";
		rockchip,grf = <0x29>;
		iommus = <0x6e>;
		iommu_enabled = <0x01>;
		reg = <0x00 0xff9b0000 0x00 0x400>;
		interrupts = <0x00 0x0d 0x04>;
		interrupt-names = "irq_dec";
		clocks = <0x02 0xca 0x02 0x1cd 0x02 0x7d 0x02 0x7e>;
		clock-names = "aclk_vcodec\0hclk_vcodec\0clk_cabac\0clk_core";
		power-domains = <0x5c 0x08>;
		resets = <0x02 0x98 0x02 0x70>;
		reset-names = "video_h\0video_a";
		dev_mode = <0x02>;
		allocator = <0x01>;
		status = "okay";
		phandle = <0xc5>;
	};

	iommu@ff9b0480 {
		compatible = "rockchip,iommu";
		reg = <0x00 0xff9b0480 0x00 0x40 0x00 0xff9b04c0 0x00 0x40>;
		interrupts = <0x00 0x0c 0x04>;
		interrupt-names = "vdec_mmu";
		clocks = <0x02 0xca 0x02 0x1cd>;
		clock-names = "aclk\0hclk";
		power-domains = <0x5c 0x08>;
		#iommu-cells = <0x00>;
		status = "okay";
		phandle = <0x6e>;
	};

	qos@ffad0000 {
		compatible = "syscon";
		reg = <0x00 0xffad0000 0x00 0x20>;
		phandle = <0x43>;
	};

	qos@ffad0080 {
		compatible = "syscon";
		reg = <0x00 0xffad0080 0x00 0x20>;
		phandle = <0x44>;
	};

	qos@ffad0100 {
		compatible = "syscon";
		reg = <0x00 0xffad0100 0x00 0x20>;
		phandle = <0x45>;
	};

	qos@ffad0180 {
		compatible = "syscon";
		reg = <0x00 0xffad0180 0x00 0x20>;
		phandle = <0x46>;
	};

	qos@ffad0200 {
		compatible = "syscon";
		reg = <0x00 0xffad0200 0x00 0x20>;
		phandle = <0x47>;
	};

	qos@ffad0300 {
		compatible = "syscon";
		reg = <0x00 0xffad0300 0x00 0x20>;
		phandle = <0x48>;
	};

	qos@ffad0380 {
		compatible = "syscon";
		reg = <0x00 0xffad0380 0x00 0x20>;
		phandle = <0x49>;
	};

	qos@ffad0400 {
		compatible = "syscon";
		reg = <0x00 0xffad0400 0x00 0x20>;
		phandle = <0x4a>;
	};

	qos@ffad0480 {
		compatible = "syscon";
		reg = <0x00 0xffad0480 0x00 0x20>;
		phandle = <0x4b>;
	};

	qos@ffad0580 {
		compatible = "syscon";
		reg = <0x00 0xffad0580 0x00 0x20>;
		phandle = <0x4c>;
	};

	qos@ffad0600 {
		compatible = "syscon";
		reg = <0x00 0xffad0600 0x00 0x20>;
		phandle = <0x4d>;
	};

	qos@ffae0000 {
		compatible = "syscon";
		reg = <0x00 0xffae0000 0x00 0x20>;
		phandle = <0x50>;
	};

	qos@ffae0080 {
		compatible = "syscon";
		reg = <0x00 0xffae0080 0x00 0x20>;
		phandle = <0x51>;
	};

	qos@ffae0100 {
		compatible = "syscon";
		reg = <0x00 0xffae0100 0x00 0x20>;
		phandle = <0x4e>;
	};

	qos@ffae0180 {
		compatible = "syscon";
		reg = <0x00 0xffae0180 0x00 0x20>;
		phandle = <0x4f>;
	};

	qos@ffaf0000 {
		compatible = "syscon";
		reg = <0x00 0xffaf0000 0x00 0x20>;
		phandle = <0x52>;
	};

	pinctrl {
		compatible = "rockchip,rk3366-pinctrl";
		rockchip,grf = <0x29>;
		rockchip,pmu = <0x6f>;
		#address-cells = <0x02>;
		#size-cells = <0x02>;
		ranges;
		phandle = <0xc6>;

		gpio0@ff750000 {
			compatible = "rockchip,gpio-bank";
			reg = <0x00 0xff750000 0x00 0x100>;
			clocks = <0x02 0x145>;
			interrupts = <0x00 0x51 0x04>;
			gpio-controller;
			#gpio-cells = <0x02>;
			interrupt-controller;
			#interrupt-cells = <0x02>;
			phandle = <0x2f>;
		};

		gpio1@ff780000 {
			compatible = "rockchip,gpio-bank";
			reg = <0x00 0xff758000 0x00 0x100>;
			clocks = <0x02 0x146>;
			interrupts = <0x00 0x52 0x04>;
			gpio-controller;
			#gpio-cells = <0x02>;
			interrupt-controller;
			#interrupt-cells = <0x02>;
			phandle = <0xc7>;
		};

		gpio2@ff790000 {
			compatible = "rockchip,gpio-bank";
			reg = <0x00 0xff790000 0x00 0x100>;
			clocks = <0x02 0x147>;
			interrupts = <0x00 0x53 0x04>;
			gpio-controller;
			#gpio-cells = <0x02>;
			interrupt-controller;
			#interrupt-cells = <0x02>;
			phandle = <0x2b>;
		};

		gpio3@ff7a0000 {
			compatible = "rockchip,gpio-bank";
			reg = <0x00 0xff7a0000 0x00 0x100>;
			clocks = <0x02 0x148>;
			interrupts = <0x00 0x54 0x04>;
			gpio-controller;
			#gpio-cells = <0x02>;
			interrupt-controller;
			#interrupt-cells = <0x02>;
			phandle = <0x88>;
		};

		gpio4@ff7b0000 {
			compatible = "rockchip,gpio-bank";
			reg = <0x00 0xff7b0000 0x00 0x100>;
			clocks = <0x02 0x149>;
			interrupts = <0x00 0x55 0x04>;
			gpio-controller;
			#gpio-cells = <0x02>;
			interrupt-controller;
			#interrupt-cells = <0x02>;
			phandle = <0xc8>;
		};

		gpio5@ff7c0000 {
			compatible = "rockchip,gpio-bank";
			reg = <0x00 0xff7c0000 0x00 0x100>;
			clocks = <0x02 0x14a>;
			interrupts = <0x00 0x57 0x04>;
			gpio-controller;
			#gpio-cells = <0x02>;
			interrupt-controller;
			#interrupt-cells = <0x02>;
			phandle = <0x79>;
		};

		pcfg-pull-up {
			bias-pull-up;
			phandle = <0x71>;
		};

		pcfg-pull-down {
			bias-pull-down;
			phandle = <0xc9>;
		};

		pcfg-pull-none {
			bias-disable;
			phandle = <0x70>;
		};

		pcfg-pull-none-12ma {
			bias-disable;
			drive-strength = <0x0c>;
			phandle = <0x72>;
		};

		emmc {

			emmc-clk {
				rockchip,pins = <0x03 0x04 0x02 0x70>;
				phandle = <0x25>;
			};

			emmc-cmd {
				rockchip,pins = <0x02 0x1a 0x02 0x71>;
				phandle = <0x26>;
			};

			emmc-pwr {
				rockchip,pins = <0x02 0x1b 0x02 0x71>;
				phandle = <0x27>;
			};

			emmc-bus1 {
				rockchip,pins = <0x02 0x12 0x02 0x71>;
				phandle = <0xca>;
			};

			emmc-bus4 {
				rockchip,pins = <0x02 0x12 0x02 0x71 0x02 0x13 0x02 0x71 0x02 0x14 0x02 0x71 0x02 0x15 0x02 0x71>;
				phandle = <0xcb>;
			};

			emmc-bus8 {
				rockchip,pins = <0x02 0x12 0x02 0x71 0x02 0x13 0x02 0x71 0x02 0x14 0x02 0x71 0x02 0x15 0x02 0x71 0x02 0x16 0x02 0x71 0x02 0x17 0x02 0x71 0x02 0x18 0x02 0x71 0x02 0x19 0x02 0x71>;
				phandle = <0x28>;
			};
		};

		sdmmc {

			sdmmc-cd {
				rockchip,pins = <0x00 0x09 0x01 0x71>;
				phandle = <0x1f>;
			};

			sdmmc-bus1 {
				rockchip,pins = <0x05 0x00 0x01 0x71>;
				phandle = <0xcc>;
			};

			sdmmc-bus4 {
				rockchip,pins = <0x05 0x00 0x01 0x71 0x05 0x01 0x01 0x71 0x05 0x02 0x01 0x71 0x05 0x03 0x01 0x71>;
				phandle = <0x20>;
			};

			sdmmc-clk {
				rockchip,pins = <0x05 0x04 0x01 0x70>;
				phandle = <0x1d>;
			};

			sdmmc-cmd {
				rockchip,pins = <0x05 0x05 0x01 0x71>;
				phandle = <0x1e>;
			};
		};

		sdio {

			sdio-bus1 {
				rockchip,pins = <0x03 0x0c 0x01 0x71>;
				phandle = <0xcd>;
			};

			sdio-bus4 {
				rockchip,pins = <0x03 0x0c 0x01 0x71 0x03 0x0d 0x01 0x71 0x03 0x0e 0x01 0x71 0x03 0x0f 0x01 0x71>;
				phandle = <0x22>;
			};

			sdio-cmd {
				rockchip,pins = <0x03 0x10 0x01 0x71>;
				phandle = <0x23>;
			};

			sdio-clk {
				rockchip,pins = <0x03 0x11 0x01 0x70>;
				phandle = <0x24>;
			};

			sdio-cd {
				rockchip,pins = <0x03 0x12 0x01 0x71>;
				phandle = <0xce>;
			};

			sdio-wp {
				rockchip,pins = <0x03 0x13 0x01 0x71>;
				phandle = <0xcf>;
			};

			sdio-int {
				rockchip,pins = <0x03 0x14 0x01 0x71>;
				phandle = <0xd0>;
			};

			sdio-pwr {
				rockchip,pins = <0x03 0x15 0x01 0x71>;
				phandle = <0xd1>;
			};
		};

		hdmi_i2c {

			hdmii2c-xfer {
				rockchip,pins = <0x05 0x0d 0x02 0x70 0x05 0x0e 0x02 0x70>;
				phandle = <0x6a>;
			};
		};

		hdmi_pin {

			hdmi-cec {
				rockchip,pins = <0x05 0x0c 0x01 0x70>;
				phandle = <0x6b>;
			};
		};

		i2c0 {

			i2c0-xfer {
				rockchip,pins = <0x00 0x03 0x01 0x70 0x00 0x04 0x01 0x70>;
				phandle = <0x2e>;
			};
		};

		i2c1 {

			i2c1-xfer {
				rockchip,pins = <0x04 0x19 0x01 0x70 0x04 0x1a 0x01 0x70>;
				phandle = <0x3e>;
			};
		};

		i2c2 {

			i2c2-xfer {
				rockchip,pins = <0x05 0x0f 0x02 0x70 0x05 0x10 0x02 0x70>;
				phandle = <0x33>;
			};

			i2c2-gpio {
				rockchip,pins = <0x05 0x0f 0x00 0x70 0x05 0x10 0x00 0x70>;
				phandle = <0x7a>;
			};
		};

		i2c3 {

			i2c3-xfer {
				rockchip,pins = <0x02 0x10 0x02 0x70 0x02 0x11 0x02 0x70>;
				phandle = <0x34>;
			};
		};

		i2c4 {

			i2c4-xfer {
				rockchip,pins = <0x05 0x08 0x01 0x70 0x05 0x09 0x01 0x70>;
				phandle = <0x35>;
			};

			i2c4-gpio {
				rockchip,pins = <0x05 0x08 0x00 0x70 0x05 0x09 0x00 0x70>;
				phandle = <0x7c>;
			};
		};

		i2c5 {

			i2c5-xfer {
				rockchip,pins = <0x05 0x0d 0x01 0x70 0x05 0x0e 0x01 0x70>;
				phandle = <0x36>;
			};

			i2c5-gpio {
				rockchip,pins = <0x05 0x0d 0x00 0x70 0x05 0x0e 0x00 0x70>;
				phandle = <0xd2>;
			};
		};

		i2s {

			i2s-8ch-bus {
				rockchip,pins = <0x04 0x10 0x01 0x70 0x04 0x11 0x01 0x70 0x04 0x12 0x01 0x70 0x04 0x13 0x01 0x70 0x04 0x14 0x01 0x70 0x04 0x15 0x01 0x70 0x04 0x16 0x01 0x70 0x04 0x17 0x01 0x70 0x04 0x18 0x01 0x70>;
				phandle = <0x56>;
			};
		};

		spdif {

			spdif-bus {
				rockchip,pins = <0x05 0x13 0x01 0x70>;
				phandle = <0x55>;
			};
		};

		spi0 {

			spi0-clk {
				rockchip,pins = <0x02 0x1d 0x02 0x71>;
				phandle = <0x0c>;
			};

			spi0-cs0 {
				rockchip,pins = <0x02 0x18 0x03 0x71>;
				phandle = <0x0f>;
			};

			spi0-cs1 {
				rockchip,pins = <0x02 0x19 0x03 0x71>;
				phandle = <0xd3>;
			};

			spi0-tx {
				rockchip,pins = <0x02 0x17 0x03 0x71>;
				phandle = <0x0d>;
			};

			spi0-rx {
				rockchip,pins = <0x02 0x16 0x03 0x71>;
				phandle = <0x0e>;
			};
		};

		spi1 {

			spi1-clk {
				rockchip,pins = <0x02 0x04 0x03 0x71>;
				phandle = <0x10>;
			};

			spi1-cs0 {
				rockchip,pins = <0x02 0x05 0x03 0x71>;
				phandle = <0x13>;
			};

			spi1-tx {
				rockchip,pins = <0x02 0x06 0x03 0x71>;
				phandle = <0x11>;
			};

			spi1-rx {
				rockchip,pins = <0x02 0x07 0x03 0x71>;
				phandle = <0x12>;
			};
		};

		scr {

			scr-clk {
				rockchip,pins = <0x05 0x08 0x02 0x70>;
				phandle = <0x17>;
			};

			scr-io {
				rockchip,pins = <0x05 0x09 0x02 0x71>;
				phandle = <0x14>;
			};

			scr-rst {
				rockchip,pins = <0x05 0x0a 0x01 0x70>;
				phandle = <0x16>;
			};

			scr-detect {
				rockchip,pins = <0x05 0x0b 0x01 0x70>;
				phandle = <0x15>;
			};
		};

		uart0 {

			uart0-xfer {
				rockchip,pins = <0x03 0x08 0x01 0x71 0x03 0x09 0x01 0x70>;
				phandle = <0x37>;
			};

			uart0-cts {
				rockchip,pins = <0x03 0x0a 0x01 0x70>;
				phandle = <0x38>;
			};

			uart0-rts {
				rockchip,pins = <0x03 0x0b 0x01 0x70>;
				phandle = <0x89>;
			};
		};

		uart2_t0 {

			uart2_t0-xfer {
				rockchip,pins = <0x00 0x16 0x01 0x71 0x00 0x15 0x01 0x70>;
				phandle = <0xd4>;
			};
		};

		uart2_t1 {

			uart2_t1-xfer {
				rockchip,pins = <0x05 0x00 0x02 0x71 0x05 0x01 0x02 0x70>;
				phandle = <0x42>;
			};
		};

		uart2_t2 {

			uart2_t2-xfer {
				rockchip,pins = <0x05 0x0e 0x03 0x71 0x05 0x0d 0x03 0x70>;
				phandle = <0xd5>;
			};
		};

		uart3 {

			uart3-xfer {
				rockchip,pins = <0x05 0x0f 0x01 0x71 0x05 0x10 0x01 0x70>;
				phandle = <0x39>;
			};

			uart3-cts {
				rockchip,pins = <0x05 0x11 0x01 0x70>;
				phandle = <0x3a>;
			};

			uart3-rts {
				rockchip,pins = <0x05 0x12 0x01 0x70>;
				phandle = <0x3b>;
			};
		};

		pwm0 {

			pwm0-pin {
				rockchip,pins = <0x00 0x08 0x01 0x70>;
				phandle = <0x3f>;
			};
		};

		pwm1 {

			pwm1-pin {
				rockchip,pins = <0x01 0x06 0x02 0x70>;
				phandle = <0x40>;
			};
		};

		pwm2_t0 {

			pwm2_t0-pin {
				rockchip,pins = <0x02 0x0f 0x03 0x70>;
				phandle = <0xd6>;
			};
		};

		pwm2_t1 {

			pwm2_t1-pin {
				rockchip,pins = <0x05 0x11 0x02 0x70>;
				phandle = <0xd7>;
			};
		};

		pwm3_t0 {

			pwm3_t0-pin {
				rockchip,pins = <0x01 0x00 0x02 0x70>;
				phandle = <0xd8>;
			};
		};

		pwm3_t1 {

			pwm3_t1-pin {
				rockchip,pins = <0x00 0x15 0x02 0x70>;
				phandle = <0xd9>;
			};
		};

		pwm3_t2 {

			pwm3_t2-pin {
				rockchip,pins = <0x05 0x12 0x02 0x70>;
				phandle = <0x41>;
			};
		};

		lcdc {

			lcdc-lcdc {
				rockchip,pins = <0x00 0x18 0x02 0x70 0x00 0x19 0x02 0x70 0x00 0x1a 0x01 0x70 0x00 0x1b 0x01 0x70 0x00 0x1c 0x01 0x70 0x00 0x1d 0x01 0x70 0x00 0x1e 0x01 0x70 0x00 0x1f 0x01 0x70 0x01 0x00 0x01 0x70 0x01 0x01 0x01 0x70 0x01 0x02 0x01 0x70 0x01 0x03 0x01 0x70 0x01 0x04 0x01 0x70 0x01 0x05 0x01 0x70 0x01 0x06 0x01 0x70 0x01 0x07 0x01 0x70 0x01 0x08 0x01 0x70 0x01 0x09 0x01 0x70>;
				phandle = <0xda>;
			};

			lcdc-gpio {
				rockchip,pins = <0x00 0x18 0x00 0x70 0x00 0x19 0x00 0x70 0x00 0x1a 0x00 0x70 0x00 0x1b 0x00 0x70 0x00 0x1c 0x00 0x70 0x00 0x1d 0x00 0x70 0x00 0x1e 0x00 0x70 0x00 0x1f 0x00 0x70 0x01 0x00 0x00 0x70 0x01 0x01 0x00 0x70 0x01 0x02 0x00 0x70 0x01 0x03 0x00 0x70 0x01 0x04 0x00 0x70 0x01 0x05 0x00 0x70 0x01 0x06 0x00 0x70 0x01 0x07 0x00 0x70 0x01 0x08 0x00 0x70 0x01 0x09 0x00 0x70>;
				phandle = <0xdb>;
			};
		};

		gmac {

			rgmii-pins {
				rockchip,pins = <0x02 0x07 0x01 0x70 0x02 0x06 0x01 0x70 0x02 0x05 0x01 0x72 0x02 0x04 0x01 0x72 0x02 0x03 0x01 0x70 0x02 0x02 0x01 0x70 0x02 0x01 0x01 0x72 0x02 0x00 0x01 0x70 0x02 0x11 0x01 0x72 0x02 0x0e 0x01 0x70 0x02 0x0d 0x01 0x70 0x02 0x0c 0x01 0x72 0x02 0x0b 0x01 0x70 0x02 0x09 0x01 0x70 0x02 0x08 0x01 0x70>;
				phandle = <0x2d>;
			};

			rmii-pins {
				rockchip,pins = <0x02 0x03 0x01 0x70 0x02 0x02 0x01 0x70 0x02 0x01 0x01 0x70 0x02 0x00 0x01 0x70 0x02 0x0e 0x01 0x70 0x02 0x0d 0x01 0x70 0x02 0x0c 0x01 0x70 0x02 0x0b 0x01 0x70 0x02 0x09 0x01 0x70 0x02 0x08 0x01 0x70>;
				phandle = <0xdc>;
			};
		};

		eth_phy {

			eth-phy-pwr {
				rockchip,pins = <0x00 0x19 0x00 0x70>;
				phandle = <0x85>;
			};
		};

		tsadc_pin {

			tsadc-gpio {
				rockchip,pins = <0x00 0x16 0x00 0x70>;
				phandle = <0x1b>;
			};

			tsadc-int {
				rockchip,pins = <0x00 0x16 0x02 0x70>;
				phandle = <0x1c>;
			};
		};

		usb2 {

			host-vbus-drv {
				rockchip,pins = <0x00 0x10 0x00 0x70>;
				phandle = <0x84>;
			};
		};

		mpu6500 {

			mpu6500-irq-gpio {
				rockchip,pins = <0x05 0x12 0x00 0x70>;
				phandle = <0x7b>;
			};
		};

		pmic {

			pmic-int-l {
				rockchip,pins = <0x00 0x02 0x00 0x71>;
				phandle = <0x30>;
			};
		};

		sdio-pwrseq {

			wifienable-h {
				rockchip,pins = <0x00 0x0e 0x00 0x70>;
				phandle = <0x87>;
			};
		};

		wireless-bluetooth {

			uart0-rts-gpios {
				rockchip,pins = <0x03 0x0b 0x00 0x70>;
				phandle = <0x8a>;
			};
		};
	};

	gpu@ffa30000 {
		compatible = "arm,malit764\0arm,malit76x\0arm,malit7xx\0arm,mali-midgard";
		reg = <0x00 0xffa30000 0x00 0x10000>;
		interrupts = <0x00 0x06 0x04 0x00 0x07 0x04 0x00 0x08 0x04>;
		interrupt-names = "GPU\0MMU\0JOB";
		clocks = <0x02 0xc4>;
		clock-names = "clk_mali";
		#cooling-cells = <0x02>;
		power-domains = <0x5c 0x0b>;
		operating-points-v2 = <0x73>;
		status = "okay";
		mali-supply = <0x74>;
		phandle = <0x1a>;

		power_model {
			compatible = "arm,mali-simple-power-model";
			voltage = <0x384>;
			frequency = <0x1f4>;
			static-power = <0x12c>;
			dynamic-power = <0x6f4>;
			ts = <0x7d00 0x125c 0xffffffb0 0x02>;
			thermal-zone = "gpu-thermal";
		};
	};

	gpu_opp_table {
		compatible = "operating-points-v2";
		opp-shared;
		phandle = <0x73>;

		opp-96000000 {
			opp-hz = <0x00 0x5b8d800>;
			opp-microvolt = <0x10c8e0>;
		};

		opp-192000000 {
			opp-hz = <0x00 0xb71b000>;
			opp-microvolt = <0x10c8e0>;
		};

		opp-288000000 {
			opp-hz = <0x00 0x112a8800>;
			opp-microvolt = <0x10c8e0>;
		};

		opp-375000000 {
			opp-hz = <0x00 0x165a0bc0>;
			opp-microvolt = <0x112a88>;
		};

		opp-480000000 {
			opp-hz = <0x00 0x1c9c3800>;
			opp-microvolt = <0x124f80>;
		};
	};

	reserved-memory {
		#address-cells = <0x02>;
		#size-cells = <0x02>;
		ranges;

		drm-logo@00000000 {
			compatible = "rockchip,drm-logo";
			reg = <0x00 0x00 0x00 0x00>;
			phandle = <0x59>;
		};
	};

	chosen {
		bootargs = "earlycon=uart8250,mmio32,0xff690000 swiotlb=1 firmware_class.path=/system/vendor/firmware";
	};

	fiq-debugger {
		compatible = "rockchip,fiq-debugger";
		rockchip,serial-id = <0x02>;
		rockchip,wake-irq = <0x00>;
		rockchip,irq-mode-enable = <0x00>;
		rockchip,baudrate = <0x16e360>;
		pinctrl-names = "default";
		pinctrl-0 = <0x42>;
		interrupts = <0x00 0x9a 0x04>;
		phandle = <0xdd>;
	};

	backlight {
		compatible = "pwm-backlight";
		pwms = <0x75 0x00 0x61a8 0x01>;
		brightness-levels = <0x00 0x01 0x02 0x03 0x04 0x05 0x06 0x07 0x08 0x09 0x0a 0x0b 0x0c 0x0d 0x0e 0x0f 0x10 0x11 0x12 0x13 0x14 0x15 0x16 0x17 0x18 0x19 0x1a 0x1b 0x1c 0x1d 0x1e 0x1f 0x20 0x21 0x22 0x23 0x24 0x25 0x26 0x27 0x28 0x29 0x2a 0x2b 0x2c 0x2d 0x2e 0x2f 0x30 0x31 0x32 0x33 0x34 0x35 0x36 0x37 0x38 0x39 0x3a 0x3b 0x3c 0x3d 0x3e 0x3f 0x40 0x41 0x42 0x43 0x44 0x45 0x46 0x47 0x48 0x49 0x4a 0x4b 0x4c 0x4d 0x4e 0x4f 0x50 0x51 0x52 0x53 0x54 0x55 0x56 0x57 0x58 0x59 0x5a 0x5b 0x5c 0x5d 0x5e 0x5f 0x60 0x61 0x62 0x63 0x64 0x65 0x66 0x67 0x68 0x69 0x6a 0x6b 0x6c 0x6d 0x6e 0x6f 0x70 0x71 0x72 0x73 0x74 0x75 0x76 0x77 0x78 0x79 0x7a 0x7b 0x7c 0x7d 0x7e 0x7f 0x80 0x81 0x82 0x83 0x84 0x85 0x86 0x87 0x88 0x89 0x8a 0x8b 0x8c 0x8d 0x8e 0x8f 0x90 0x91 0x92 0x93 0x94 0x95 0x96 0x97 0x98 0x99 0x9a 0x9b 0x9c 0x9d 0x9e 0x9f 0xa0 0xa1 0xa2 0xa3 0xa4 0xa5 0xa6 0xa7 0xa8 0xa9 0xaa 0xab 0xac 0xad 0xae 0xaf 0xb0 0xb1 0xb2 0xb3 0xb4 0xb5 0xb6 0xb7 0xb8 0xb9 0xba 0xbb 0xbc 0xbd 0xbe 0xbf 0xc0 0xc1 0xc2 0xc3 0xc4 0xc5 0xc6 0xc7 0xc8 0xc9 0xca 0xcb 0xcc 0xcd 0xce 0xcf 0xd0 0xd1 0xd2 0xd3 0xd4 0xd5 0xd6 0xd7 0xd8 0xd9 0xda 0xdb 0xdc 0xdd 0xde 0xdf 0xe0 0xe1 0xe2 0xe3 0xe4 0xe5 0xe6 0xe7 0xe8 0xe9 0xea 0xeb 0xec 0xed 0xee 0xef 0xf0 0xf1 0xf2 0xf3 0xf4 0xf5 0xf6 0xf7 0xf8 0xf9 0xfa 0xfb 0xfc 0xfd 0xfe 0xff>;
		default-brightness-level = <0xc8>;
		enable-gpios = <0x2f 0x1a 0x00>;
		phandle = <0x67>;
	};

	dwc-control-usb {
		compatible = "rockchip,rk3368-dwc-control-usb";
		rockchip,grf = <0x29>;
		grf-offset = <0x49c>;
		interrupts = <0x00 0x5d 0x04 0x00 0x5e 0x04 0x00 0x5f 0x04 0x00 0x60 0x04>;
		interrupt-names = "otg_id\0otg_bvalid\0otg_linestate\0host0_linestate";
		clocks = <0x02 0x79 0x02 0x1c5>;
		clock-names = "sclk_otgphy0\0otg";
		otg_drv_gpio = <0x2f 0x0a 0x01>;
		rockchip,remote_wakeup;
		rockchip,usb_irq_wakeup;
		phandle = <0xde>;

		usb_bc {
			compatible = "inno,phy";
			regbase = "/dwc-control-usb";
			rk_usb,bvalid = <0x49c 0x17 0x01>;
			rk_usb,iddig = <0x49c 0x1a 0x01>;
			rk_usb,vdmsrcen = <0x718 0x0c 0x01>;
			rk_usb,vdpsrcen = <0x718 0x0b 0x01>;
			rk_usb,rdmpden = <0x718 0x0a 0x01>;
			rk_usb,idpsrcen = <0x718 0x09 0x01>;
			rk_usb,idmsinken = <0x718 0x08 0x01>;
			rk_usb,idpsinken = <0x718 0x07 0x01>;
			rk_usb,dpattach = <0x498 0x1f 0x01>;
			rk_usb,cpdet = <0x498 0x1e 0x01>;
			rk_usb,dcpattach = <0x498 0x1d 0x01>;
		};
	};

	external-gmac-clock {
		compatible = "fixed-clock";
		clock-frequency = <0x7735940>;
		clock-output-names = "ext_gmac";
		#clock-cells = <0x00>;
		phandle = <0x2c>;
	};

	ion {
		compatible = "rockchip,ion";
		#address-cells = <0x01>;
		#size-cells = <0x00>;

		cma-heap {
			reg = <0x00 0x2000000>;
		};

		system-heap {
		};
	};

	io-domains {
		compatible = "rockchip,rk3366-io-voltage-domain";
		rockchip,grf = <0x29>;
		lcdc-supply = <0x32>;
		dvpts-supply = <0x76>;
		wifibt-supply = <0x77>;
		audio-supply = <0x32>;
		sdcard-supply = <0x78>;
		tphdsor-supply = <0x32>;
	};

	i2c@2 {
		compatible = "i2c-gpio";
		gpios = <0x79 0x0f 0x00 0x79 0x10 0x00>;
		i2c-gpio,delay-us = <0x02>;
		#address-cells = <0x01>;
		#size-cells = <0x00>;
		pinctrl-names = "default";
		pinctrl-0 = <0x7a>;
		status = "disabled";

		mpu6050@68 {
			status = "disabled";
			compatible = "invensense,mpu6050";
			pinctrl-names = "default";
			pinctrl-0 = <0x7b>;
			reg = <0x68>;
			irq-gpio = <0x79 0x12 0x01>;
			mpu-int_config = <0x10>;
			mpu-level_shifter = <0x00>;
			mpu-orientation = <0x00 0x01 0x00 0x01 0x00 0x00 0x00 0x00 0x01>;
			orientation-x = <0x00>;
			orientation-y = <0x01>;
			orientation-z = <0x00>;
			support-hw-poweroff = <0x00>;
			mpu-debug = <0x01>;
		};
	};

	i2c@4 {
		compatible = "i2c-gpio";
		gpios = <0x79 0x09 0x00 0x79 0x08 0x00>;
		i2c-gpio,delay-us = <0x02>;
		#address-cells = <0x01>;
		#size-cells = <0x00>;
		pinctrl-names = "default";
		pinctrl-0 = <0x7c>;
		status = "okay";

		gt9xx@14 {
			compatible = "goodix,gt9xx";
			reg = <0x14>;
			touch-gpio = <0x79 0x0b 0x08>;
			reset-gpio = <0x79 0x0a 0x00>;
			max-x = <0x4b0>;
			max-y = <0x76c>;
			tp-size = <0x38f>;
			tp-supply = <0x7d>;
			status = "okay";
			phandle = <0xdf>;
		};
	};

	ramoops_mem {
		reg = <0x00 0x100000 0x00 0x100000>;
		reg-names = "ramoops_mem";
		phandle = <0x7e>;
	};

	ramoops {
		compatible = "ramoops";
		record-size = <0x00 0x10000>;
		console-size = <0x00 0x80000>;
		ftrace-size = <0x00 0x10000>;
		pmsg-size = <0x00 0x50000>;
		memory-region = <0x7e>;
	};

	rockchip-key {
		compatible = "rockchip,key";
		status = "okay";
		io-channels = <0x7f 0x01>;
		phandle = <0xe0>;

		vol-up-key {
			linux,code = <0x73>;
			label = "volume up";
			rockchip,adc_value = <0x01>;
		};

		vol-down-key {
			linux,code = <0x72>;
			label = "volume down";
			rockchip,adc_value = <0xaa>;
		};

		power-key {
			gpios = <0x2f 0x0b 0x01>;
			linux,code = <0x74>;
			label = "power";
			gpio-key,wakeup;
		};

		menu-key {
			linux,code = <0x3b>;
			label = "menu";
			rockchip,adc_value = <0x163>;
		};

		home-key {
			linux,code = <0x66>;
			label = "home";
			rockchip,adc_value = <0x2ea>;
		};

		back-key {
			linux,code = <0x9e>;
			label = "back";
			rockchip,adc_value = <0x230>;
		};

		camera-key {
			linux,code = <0xd4>;
			label = "camera";
			rockchip,adc_value = <0x1c2>;
		};
	};

	rt5640-sound {
		compatible = "simple-audio-card";
		simple-audio-card,format = "i2s";
		simple-audio-card,name = "rockchip,rt5640-codec";
		simple-audio-card,mclk-fs = <0x100>;
		simple-audio-card,widgets = "Microphone\0Mic Jack\0Headphone\0Headphone Jack";
		simple-audio-card,routing = "Mic Jack\0MICBIAS1\0IN1P\0Mic Jack\0Headphone Jack\0HPOL\0Headphone Jack\0HPOR";

		simple-audio-card,cpu {
			sound-dai = <0x80>;
		};

		simple-audio-card,codec {
			sound-dai = <0x81>;
		};
	};

	spdif-sound {
		compatible = "simple-audio-card";
		simple-audio-card,name = "rockchip,spdif";

		simple-audio-card,cpu {
			sound-dai = <0x82>;
		};

		simple-audio-card,codec {
			sound-dai = <0x83>;
		};
	};

	spdif-out {
		compatible = "linux,spdif-dit";
		#sound-dai-cells = <0x00>;
		phandle = <0x83>;
	};

	vcc-sys {
		compatible = "regulator-fixed";
		regulator-name = "vcc_sys";
		regulator-always-on;
		regulator-boot-on;
		regulator-min-microvolt = <0x39fbc0>;
		regulator-max-microvolt = <0x39fbc0>;
		phandle = <0x31>;
	};

	vbus-host-regulator {
		compatible = "regulator-fixed";
		enable-active-high;
		gpio = <0x2f 0x10 0x00>;
		pinctrl-names = "default";
		pinctrl-0 = <0x84>;
		regulator-name = "vbus_host";
		phandle = <0x53>;
	};

	vcc-phy-regulator {
		compatible = "regulator-fixed";
		enable-active-high;
		gpio = <0x2f 0x19 0x00>;
		pinctrl-names = "default";
		pinctrl-0 = <0x85>;
		regulator-name = "vcc_phy";
		regulator-always-on;
		regulator-boot-on;
		phandle = <0x2a>;
	};

	xin32k {
		compatible = "fixed-clock";
		clock-frequency = <0x8000>;
		clock-output-names = "xin32k";
		#clock-cells = <0x00>;
		phandle = <0xe1>;
	};

	sdio-pwrseq {
		compatible = "mmc-pwrseq-simple";
		clocks = <0x86 0x01>;
		clock-names = "ext_clock";
		pinctrl-names = "default";
		pinctrl-0 = <0x87>;
		reset-gpios = <0x2f 0x0e 0x01>;
		phandle = <0x21>;
	};

	wireless-wlan {
		compatible = "wlan-platdata";
		rockchip,grf = <0x29>;
		wifi_chip_type = "ap6335";
		sdio_vref = <0x708>;
		WIFI,host_wake_irq = <0x88 0x14 0x00>;
		status = "okay";
	};

	wireless-bluetooth {
		compatible = "bluetooth-platdata";
		uart_rts_gpios = <0x88 0x0b 0x01>;
		pinctrl-names = "default\0rts_gpio";
		pinctrl-0 = <0x89>;
		pinctrl-1 = <0x8a>;
		BT,reset_gpio = <0x88 0x13 0x00>;
		BT,wake_gpio = <0x88 0x12 0x00>;
		BT,wake_host_irq = <0x88 0x15 0x00>;
		status = "okay";
	};

	__symbols__ {
		cpu0 = "/cpus/cpu@0";
		cpu1 = "/cpus/cpu@1";
		cpu2 = "/cpus/cpu@2";
		cpu3 = "/cpus/cpu@3";
		CPU_SLEEP = "/cpus/idle-states/cpu-sleep";
		CLUSTER_SLEEP = "/cpus/idle-states/cluster-sleep";
		cpu0_opp_table = "/opp_table0";
		xin24m = "/xin24m";
		gic = "/interrupt-controller@ffb71000";
		nandc0 = "/nandc@ff0c0000";
		saradc = "/saradc@ff100000";
		spi0 = "/spi@ff110000";
		spi1 = "/spi@ff120000";
		scr = "/rkscr@ff1d0000";
		soc_thermal = "/thermal-zones/soc-thermal";
		threshold = "/thermal-zones/soc-thermal/trips/trip-point-0";
		target = "/thermal-zones/soc-thermal/trips/trip-point-1";
		soc_crit = "/thermal-zones/soc-thermal/trips/soc-crit";
		gpu_thermal = "/thermal-zones/gpu-thermal";
		tsadc = "/tsadc@ff260000";
		sdmmc = "/dwmmc@ff400000";
		sdio = "/dwmmc@ff410000";
		emmc = "/dwmmc@ff420000";
		gmac = "/eth@ff440000";
		i2c0 = "/i2c@ff650000";
		syr827 = "/i2c@ff650000/syr827@40";
		rk818 = "/i2c@ff650000/pmic@1c";
		vdd_logic = "/i2c@ff650000/pmic@1c/regulators/DCDC_REG1";
		vdd_gpu = "/i2c@ff650000/pmic@1c/regulators/DCDC_REG2";
		vcc_ddr = "/i2c@ff650000/pmic@1c/regulators/DCDC_REG3";
		vcc_io = "/i2c@ff650000/pmic@1c/regulators/DCDC_REG4";
		vcca_codec = "/i2c@ff650000/pmic@1c/regulators/LDO_REG1";
		vcc_tp = "/i2c@ff650000/pmic@1c/regulators/LDO_REG2";
		vdd_10 = "/i2c@ff650000/pmic@1c/regulators/LDO_REG3";
		vcc18_lcd = "/i2c@ff650000/pmic@1c/regulators/LDO_REG4";
		vccio_pmu = "/i2c@ff650000/pmic@1c/regulators/LDO_REG5";
		vdd10_lcd = "/i2c@ff650000/pmic@1c/regulators/LDO_REG6";
		vcc_18 = "/i2c@ff650000/pmic@1c/regulators/LDO_REG7";
		vccio_wl = "/i2c@ff650000/pmic@1c/regulators/LDO_REG8";
		vccio_sd = "/i2c@ff650000/pmic@1c/regulators/LDO_REG9";
		vcc_sd = "/i2c@ff650000/pmic@1c/regulators/SWITCH_REG";
		i2c2 = "/i2c@ff140000";
		i2c3 = "/i2c@ff150000";
		i2c4 = "/i2c@ff160000";
		i2c5 = "/i2c@ff170000";
		uart0 = "/serial@ff180000";
		uart3 = "/serial@ff1b0000";
		usb_host0_ehci = "/usb@ff480000";
		usb_host0_ohci = "/usb@ff4a0000";
		usb_otg = "/usb@ff4c0000";
		i2c1 = "/i2c@ff660000";
		rt5640 = "/i2c@ff660000/rt5640@1c";
		efuse = "/efuse@ff670000";
		cpu_leakage = "/efuse@ff670000/cpu-leakage";
		gpu_leakage = "/efuse@ff670000/gpu-leakage";
		logic_leakage = "/efuse@ff670000/logic-leakage";
		wafer_info = "/efuse@ff670000/wafer-info";
		pwm0 = "/pwm@ff680000";
		pwm1 = "/pwm@ff680010";
		pwm2 = "/pwm@ff680020";
		pwm3 = "/pwm@ff680030";
		uart2 = "/serial@ff690000";
		pmu = "/power-management@ff730000";
		power = "/power-management@ff730000/power-controller";
		pmugrf = "/syscon@ff738000";
		pmu_pvtm = "/syscon@ff738000/pmu-pvtm";
		dmac_peri = "/amba/dma-controller@ff250000";
		dmac_bus = "/amba/dma-controller@ff600000";
		cru = "/clock-controller@ff760000";
		grf = "/syscon@ff770000";
		u2phy = "/syscon@ff770000/usb2-phy@700";
		u2phy_host = "/syscon@ff770000/usb2-phy@700/host-port";
		pvtm = "/syscon@ff770000/pvtm";
		wdt = "/watchdog@ff800000";
		rktimer = "/rktimer@ff810000";
		spdif = "/spdif@ff880000";
		i2s_2ch = "/i2s-2ch@ff890000";
		i2s_8ch = "/i2s-8ch@ff898000";
		display_subsystem = "/display-subsystem";
		route_dsi = "/display-subsystem/route/route-dsi";
		route_lvds = "/display-subsystem/route/route-lvds";
		vopl = "/vop@ff8f0000";
		vopl_out = "/vop@ff8f0000/port";
		vopl_out_dsi = "/vop@ff8f0000/port/endpoint@0";
		vopl_out_lvds = "/vop@ff8f0000/port/endpoint@1";
		vopl_mmu = "/iommu@ff8f0f00";
		iep = "/iep@ff900000";
		iep_mmu = "/iommu@ff900800";
		rga = "/rga@ff920000";
		vopb = "/vop@ff930000";
		vopb_out = "/vop@ff930000/port";
		vopb_out_dsi = "/vop@ff930000/port/endpoint@0";
		vopb_out_lvds = "/vop@ff930000/port/endpoint@1";
		vopb_out_hdmi = "/vop@ff930000/port/endpoint@2";
		vopb_mmu = "/iommu@ff932400";
		dsi = "/dsi@ff960000";
		dsi_in_vopb = "/dsi@ff960000/ports/port/endpoint@0";
		dsi_in_vopl = "/dsi@ff960000/ports/port/endpoint@1";
		timing0 = "/dsi@ff960000/panel@0/display-timings/timing0";
		mipi_dphy = "/mipi-dphy@ff968000";
		lvds = "/lvds@ff968000";
		lvds_in_vopb = "/lvds@ff968000/ports/port@0/endpoint@0";
		lvds_in_vopl = "/lvds@ff968000/ports/port@0/endpoint@1";
		hdmi = "/hdmi@ff980000";
		hdmi_in_vopb = "/hdmi@ff980000/ports/port/endpoint@0";
		vpu = "/vpu_service@ff9a0000";
		vpu_mmu = "/iommu@ff9a0800";
		rkvdec = "/rkvdec@ff9b0000";
		vdec_mmu = "/iommu@ff9b0480";
		qos_iep = "/qos@ffad0000";
		qos_isp_r0 = "/qos@ffad0080";
		qos_isp_r1 = "/qos@ffad0100";
		qos_isp_w0 = "/qos@ffad0180";
		qos_isp_w1 = "/qos@ffad0200";
		qos_vop0_w = "/qos@ffad0300";
		qos_rga_r = "/qos@ffad0380";
		qos_rga_w = "/qos@ffad0400";
		qos_vop0_r = "/qos@ffad0480";
		qos_vop1_r = "/qos@ffad0580";
		qos_hdcp = "/qos@ffad0600";
		qos_rkvdec_r = "/qos@ffae0000";
		qos_rkvdec_w = "/qos@ffae0080";
		qos_vpu_r = "/qos@ffae0100";
		qos_vpu_w = "/qos@ffae0180";
		qos_gpu = "/qos@ffaf0000";
		pinctrl = "/pinctrl";
		gpio0 = "/pinctrl/gpio0@ff750000";
		gpio1 = "/pinctrl/gpio1@ff780000";
		gpio2 = "/pinctrl/gpio2@ff790000";
		gpio3 = "/pinctrl/gpio3@ff7a0000";
		gpio4 = "/pinctrl/gpio4@ff7b0000";
		gpio5 = "/pinctrl/gpio5@ff7c0000";
		pcfg_pull_up = "/pinctrl/pcfg-pull-up";
		pcfg_pull_down = "/pinctrl/pcfg-pull-down";
		pcfg_pull_none = "/pinctrl/pcfg-pull-none";
		pcfg_pull_none_12ma = "/pinctrl/pcfg-pull-none-12ma";
		emmc_clk = "/pinctrl/emmc/emmc-clk";
		emmc_cmd = "/pinctrl/emmc/emmc-cmd";
		emmc_pwr = "/pinctrl/emmc/emmc-pwr";
		emmc_bus1 = "/pinctrl/emmc/emmc-bus1";
		emmc_bus4 = "/pinctrl/emmc/emmc-bus4";
		emmc_bus8 = "/pinctrl/emmc/emmc-bus8";
		sdmmc_cd = "/pinctrl/sdmmc/sdmmc-cd";
		sdmmc_bus1 = "/pinctrl/sdmmc/sdmmc-bus1";
		sdmmc_bus4 = "/pinctrl/sdmmc/sdmmc-bus4";
		sdmmc_clk = "/pinctrl/sdmmc/sdmmc-clk";
		sdmmc_cmd = "/pinctrl/sdmmc/sdmmc-cmd";
		sdio_bus1 = "/pinctrl/sdio/sdio-bus1";
		sdio_bus4 = "/pinctrl/sdio/sdio-bus4";
		sdio_cmd = "/pinctrl/sdio/sdio-cmd";
		sdio_clk = "/pinctrl/sdio/sdio-clk";
		sdio_cd = "/pinctrl/sdio/sdio-cd";
		sdio_wp = "/pinctrl/sdio/sdio-wp";
		sdio_int = "/pinctrl/sdio/sdio-int";
		sdio_pwr = "/pinctrl/sdio/sdio-pwr";
		hdmii2c_xfer = "/pinctrl/hdmi_i2c/hdmii2c-xfer";
		hdmi_cec = "/pinctrl/hdmi_pin/hdmi-cec";
		i2c0_xfer = "/pinctrl/i2c0/i2c0-xfer";
		i2c1_xfer = "/pinctrl/i2c1/i2c1-xfer";
		i2c2_xfer = "/pinctrl/i2c2/i2c2-xfer";
		i2c2_gpio = "/pinctrl/i2c2/i2c2-gpio";
		i2c3_xfer = "/pinctrl/i2c3/i2c3-xfer";
		i2c4_xfer = "/pinctrl/i2c4/i2c4-xfer";
		i2c4_gpio = "/pinctrl/i2c4/i2c4-gpio";
		i2c5_xfer = "/pinctrl/i2c5/i2c5-xfer";
		i2c5_gpio = "/pinctrl/i2c5/i2c5-gpio";
		i2s_8ch_bus = "/pinctrl/i2s/i2s-8ch-bus";
		spdif_bus = "/pinctrl/spdif/spdif-bus";
		spi0_clk = "/pinctrl/spi0/spi0-clk";
		spi0_cs0 = "/pinctrl/spi0/spi0-cs0";
		spi0_cs1 = "/pinctrl/spi0/spi0-cs1";
		spi0_tx = "/pinctrl/spi0/spi0-tx";
		spi0_rx = "/pinctrl/spi0/spi0-rx";
		spi1_clk = "/pinctrl/spi1/spi1-clk";
		spi1_cs0 = "/pinctrl/spi1/spi1-cs0";
		spi1_tx = "/pinctrl/spi1/spi1-tx";
		spi1_rx = "/pinctrl/spi1/spi1-rx";
		scr_clk = "/pinctrl/scr/scr-clk";
		scr_io = "/pinctrl/scr/scr-io";
		scr_rst = "/pinctrl/scr/scr-rst";
		scr_detect = "/pinctrl/scr/scr-detect";
		uart0_xfer = "/pinctrl/uart0/uart0-xfer";
		uart0_cts = "/pinctrl/uart0/uart0-cts";
		uart0_rts = "/pinctrl/uart0/uart0-rts";
		uart2_t0_xfer = "/pinctrl/uart2_t0/uart2_t0-xfer";
		uart2_t1_xfer = "/pinctrl/uart2_t1/uart2_t1-xfer";
		uart2_t2_xfer = "/pinctrl/uart2_t2/uart2_t2-xfer";
		uart3_xfer = "/pinctrl/uart3/uart3-xfer";
		uart3_cts = "/pinctrl/uart3/uart3-cts";
		uart3_rts = "/pinctrl/uart3/uart3-rts";
		pwm0_pin = "/pinctrl/pwm0/pwm0-pin";
		pwm1_pin = "/pinctrl/pwm1/pwm1-pin";
		pwm2_t0_pin = "/pinctrl/pwm2_t0/pwm2_t0-pin";
		pwm2_t1_pin = "/pinctrl/pwm2_t1/pwm2_t1-pin";
		pwm3_t0_pin = "/pinctrl/pwm3_t0/pwm3_t0-pin";
		pwm3_t1_pin = "/pinctrl/pwm3_t1/pwm3_t1-pin";
		pwm3_t2_pin = "/pinctrl/pwm3_t2/pwm3_t2-pin";
		lcdc_lcdc = "/pinctrl/lcdc/lcdc-lcdc";
		lcdc_gpio = "/pinctrl/lcdc/lcdc-gpio";
		rgmii_pins = "/pinctrl/gmac/rgmii-pins";
		rmii_pins = "/pinctrl/gmac/rmii-pins";
		eth_phy_pwr = "/pinctrl/eth_phy/eth-phy-pwr";
		tsadc_gpio = "/pinctrl/tsadc_pin/tsadc-gpio";
		tsadc_int = "/pinctrl/tsadc_pin/tsadc-int";
		host_vbus_drv = "/pinctrl/usb2/host-vbus-drv";
		mpu6500_irq_gpio = "/pinctrl/mpu6500/mpu6500-irq-gpio";
		pmic_int_l = "/pinctrl/pmic/pmic-int-l";
		wifi_enable_h = "/pinctrl/sdio-pwrseq/wifienable-h";
		uart0_rts_gpio = "/pinctrl/wireless-bluetooth/uart0-rts-gpios";
		gpu = "/gpu@ffa30000";
		gpu_opp_table = "/gpu_opp_table";
		drm_logo = "/reserved-memory/drm-logo@00000000";
		fiq_debugger = "/fiq-debugger";
		backlight = "/backlight";
		dwc_control_usb = "/dwc-control-usb";
		ext_gmac = "/external-gmac-clock";
		gt9xx = "/i2c@4/gt9xx@14";
		ramoops_mem = "/ramoops_mem";
		rk_key = "/rockchip-key";
		spdif_out = "/spdif-out";
		vcc_sys = "/vcc-sys";
		vbus_host = "/vbus-host-regulator";
		vcc_phy = "/vcc-phy-regulator";
		xin32k = "/xin32k";
		sdio_pwrseq = "/sdio-pwrseq";
	};
};
